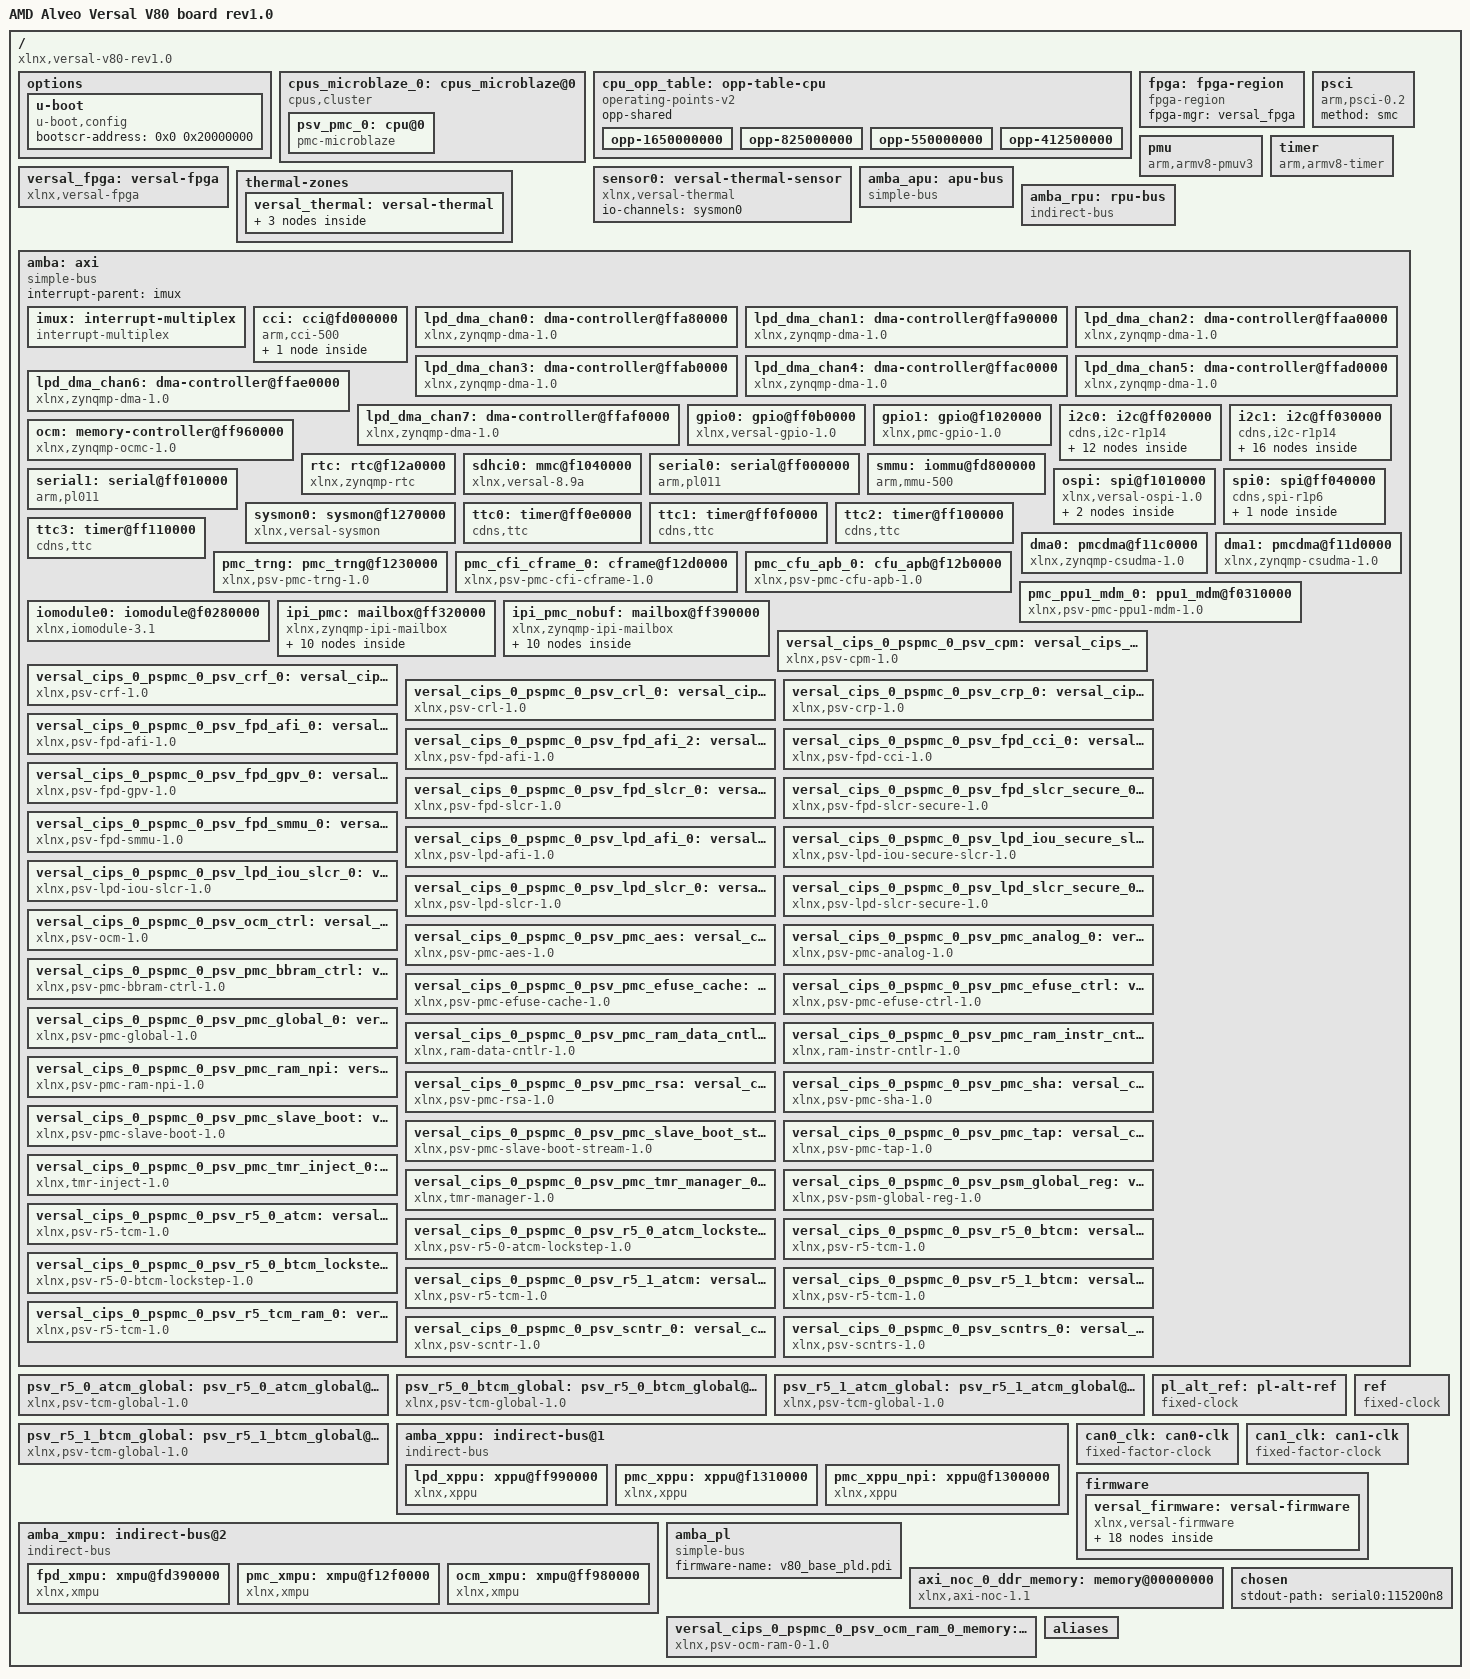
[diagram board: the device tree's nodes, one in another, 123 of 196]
/dts-v1/;
/ {
        compatible = "xlnx,versal-v80-rev1.0", "xlnx,versal";
        #address-cells = <0x2>;
        #size-cells = <0x2>;
        model = "AMD Alveo Versal V80 board rev1.0";
        board = "v80";
        device_id = "xcv80";
        slrcount = <0x3>;
        family = "Versal";
        speed_grade = "2MHP";
        pruned-sdt = <0x1>;

        options {

                u-boot {
                        compatible = "u-boot,config";
                        bootscr-address = <0x0 0x20000000>;
                };
        };

        cpus_microblaze_0: cpus_microblaze@0 {
                #address-cells = <0x1>;
                #size-cells = <0x0>;
                compatible = "cpus,cluster";
                address-map = <0xf0000000 &amba 0xf0000000 0x10000000>,
                 <0x0 &axi_noc_0_ddr_memory 0x0 0x80000000>,
                 <0xff320000 &ipi_pmc 0xff320000 0x10000>,
                 <0xff390000 &ipi_pmc_nobuf 0xff390000 0x10000>,
                 <0xfffc0000 &versal_cips_0_pspmc_0_psv_ocm_ram_0_memory 0xfffc0000 0x40000>,
                 <0xf0310000 &pmc_ppu1_mdm_0 0xf0310000 0x8000>,
                 <0xf1010000 &ospi 0xf1010000 0x10000>,
                 <0xf1020000 &gpio1 0xf1020000 0x10000>,
                 <0xf1040000 &sdhci0 0xf1040000 0x10000>,
                 <0xf1110000 &versal_cips_0_pspmc_0_psv_pmc_global_0 0xf1110000 0x50000>,
                 <0xf1160000 &versal_cips_0_pspmc_0_psv_pmc_analog_0 0xf1160000 0x30000>,
                 <0xf11a0000 &versal_cips_0_pspmc_0_psv_pmc_tap 0xf11a0000 0x20000>,
                 <0xf11c0000 &dma0 0xf11c0000 0x10000>,
                 <0xf11d0000 &dma1 0xf11d0000 0x10000>,
                 <0xf11e0000 &versal_cips_0_pspmc_0_psv_pmc_aes 0xf11e0000 0x10000>,
                 <0xf11f0000 &versal_cips_0_pspmc_0_psv_pmc_bbram_ctrl 0xf11f0000 0x10000>,
                 <0xf1200000 &versal_cips_0_pspmc_0_psv_pmc_rsa 0xf1200000 0x10000>,
                 <0xf1210000 &versal_cips_0_pspmc_0_psv_pmc_sha 0xf1210000 0x10000>,
                 <0xf1220000 &versal_cips_0_pspmc_0_psv_pmc_slave_boot 0xf1220000 0x10000>,
                 <0xf1230000 &pmc_trng 0xf1230000 0x10000>,
                 <0xf1240000 &versal_cips_0_pspmc_0_psv_pmc_efuse_ctrl 0xf1240000 0x10000>,
                 <0xf1250000 &versal_cips_0_pspmc_0_psv_pmc_efuse_cache 0xf1250000 0x10000>,
                 <0xf1260000 &versal_cips_0_pspmc_0_psv_crp_0 0xf1260000 0x10000>,
                 <0xf1270000 &sysmon0 0xf1270000 0x30000>,
                 <0xf12a0000 &rtc 0xf12a0000 0x10000>,
                 <0xf12b0000 &pmc_cfu_apb_0 0xf12b0000 0x10000>,
                 <0xf12d0000 &pmc_cfi_cframe_0 0xf12d0000 0x1000>,
                 <0xf12f0000 &pmc_xmpu 0xf12f0000 0x10000>,
                 <0xf1300000 &pmc_xppu_npi 0xf1300000 0x10000>,
                 <0xf1310000 &pmc_xppu 0xf1310000 0x10000>,
                 <0xf2100000 &versal_cips_0_pspmc_0_psv_pmc_slave_boot_stream 0xf2100000 0x10000>,
                 <0xf6000000 &versal_cips_0_pspmc_0_psv_pmc_ram_npi 0xf6000000 0x2000000>,
                 <0x0 &versal_cips_0_pspmc_0_psv_cpm 0x0 0xfd000000>,
                 <0xfd000000 &cci 0xfd000000 0x100000>,
                 <0xfd1a0000 &versal_cips_0_pspmc_0_psv_crf_0 0xfd1a0000 0x140000>,
                 <0xfd360000 &versal_cips_0_pspmc_0_psv_fpd_afi_0 0xfd360000 0x10000>,
                 <0xfd380000 &versal_cips_0_pspmc_0_psv_fpd_afi_2 0xfd380000 0x10000>,
                 <0xfd390000 &fpd_xmpu 0xfd390000 0x10000>,
                 <0xfd5e0000 &versal_cips_0_pspmc_0_psv_fpd_cci_0 0xfd5e0000 0x10000>,
                 <0xfd5f0000 &versal_cips_0_pspmc_0_psv_fpd_smmu_0 0xfd5f0000 0x10000>,
                 <0xfd610000 &versal_cips_0_pspmc_0_psv_fpd_slcr_0 0xfd610000 0x10000>,
                 <0xfd690000 &versal_cips_0_pspmc_0_psv_fpd_slcr_secure_0 0xfd690000 0x10000>,
                 <0xfd700000 &versal_cips_0_pspmc_0_psv_fpd_gpv_0 0xfd700000 0x100000>,
                 <0xfd800000 &smmu 0xfd800000 0x800000>,
                 <0xff000000 &serial0 0xff000000 0x10000>,
                 <0xff010000 &serial1 0xff010000 0x10000>,
                 <0xff020000 &i2c0 0xff020000 0x10000>,
                 <0xff030000 &i2c1 0xff030000 0x10000>,
                 <0xff040000 &spi0 0xff040000 0x10000>,
                 <0xff080000 &versal_cips_0_pspmc_0_psv_lpd_iou_slcr_0 0xff080000 0x20000>,
                 <0xff0a0000 &versal_cips_0_pspmc_0_psv_lpd_iou_secure_slcr_0 0xff0a0000 0x10000>,
                 <0xff0b0000 &gpio0 0xff0b0000 0x10000>,
                 <0xff0e0000 &ttc0 0xff0e0000 0x10000>,
                 <0xff0f0000 &ttc1 0xff0f0000 0x10000>,
                 <0xff100000 &ttc2 0xff100000 0x10000>,
                 <0xff110000 &ttc3 0xff110000 0x10000>,
                 <0xff130000 &versal_cips_0_pspmc_0_psv_scntr_0 0xff130000 0x10000>,
                 <0xff140000 &versal_cips_0_pspmc_0_psv_scntrs_0 0xff140000 0x10000>,
                 <0xff410000 &versal_cips_0_pspmc_0_psv_lpd_slcr_0 0xff410000 0x100000>,
                 <0xff510000 &versal_cips_0_pspmc_0_psv_lpd_slcr_secure_0 0xff510000 0x40000>,
                 <0xff5e0000 &versal_cips_0_pspmc_0_psv_crl_0 0xff5e0000 0x300000>,
                 <0xff960000 &versal_cips_0_pspmc_0_psv_ocm_ctrl 0xff960000 0x10000>,
                 <0xff980000 &ocm_xmpu 0xff980000 0x10000>,
                 <0xff990000 &lpd_xppu 0xff990000 0x10000>,
                 <0xff9b0000 &versal_cips_0_pspmc_0_psv_lpd_afi_0 0xff9b0000 0x10000>,
                 <0xffa80000 &lpd_dma_chan0 0xffa80000 0x10000>,
                 <0xffa90000 &lpd_dma_chan1 0xffa90000 0x10000>,
                 <0xffaa0000 &lpd_dma_chan2 0xffaa0000 0x10000>,
                 <0xffab0000 &lpd_dma_chan3 0xffab0000 0x10000>,
                 <0xffac0000 &lpd_dma_chan4 0xffac0000 0x10000>,
                 <0xffad0000 &lpd_dma_chan5 0xffad0000 0x10000>,
                 <0xffae0000 &lpd_dma_chan6 0xffae0000 0x10000>,
                 <0xffaf0000 &lpd_dma_chan7 0xffaf0000 0x10000>,
                 <0xffc90000 &versal_cips_0_pspmc_0_psv_psm_global_reg 0xffc90000 0xf000>,
                 <0xffe00000 &psv_r5_0_atcm_global 0xffe00000 0x40000>,
                 <0xffe90000 &psv_r5_1_atcm_global 0xffe90000 0x10000>,
                 <0xffeb0000 &psv_r5_1_btcm_global 0xffeb0000 0x10000>,
                 <0xf0083000 &versal_cips_0_pspmc_0_psv_pmc_tmr_inject_0 0xf0083000 0x1000>,
                 <0xf0200000 &versal_cips_0_pspmc_0_psv_pmc_ram_instr_cntlr 0xf0200000 0x40000>,
                 <0xf0240000 &versal_cips_0_pspmc_0_psv_pmc_ram_data_cntlr 0xf0240000 0x20000>,
                 <0xf0280000 &iomodule0 0xf0280000 0x1000>,
                 <0xf0283000 &versal_cips_0_pspmc_0_psv_pmc_tmr_manager_0 0xf0283000 0x1000>;
                #ranges-address-cells = <0x1>;
                #ranges-size-cells = <0x1>;
                phandle = <0xa3>;

                psv_pmc_0: cpu@0 {
                        compatible = "pmc-microblaze";
                        device_type = "cpu";
                        reg = <0x0>;
                        operating-points-v2 = <&cpu_opp_table>;
                        xlnx,d-axi = <0x1>;
                        xlnx,addr-tag-bits = <0x0>;
                        xlnx,m-axi-dc-thread-id-width = <0x1>;
                        xlnx,m0-axis-protocol = "GENERIC";
                        xlnx,dcache-force-tag-lutram = <0x0>;
                        xlnx,interrupt-is-edge = <0x0>;
                        xlnx,use-mmu = <0x0>;
                        xlnx,m-axi-dp-exclusive-access = <0x0>;
                        xlnx,use-reorder-instr = <0x1>;
                        xlnx,m14-axis-protocol = "GENERIC";
                        xlnx,use-div = <0x1>;
                        xlnx,dc-axi-mon = <0x0>;
                        xlnx,m-axi-ic-user-signals = <0x0>;
                        xlnx,use-config-reset = <0x0>;
                        xlnx,s14-axis-protocol = "GENERIC";
                        xlnx,mmu-zones = <0x10>;
                        xlnx,enable-discrete-ports = <0x0>;
                        xlnx,d-lmb = <0x1>;
                        xlnx,m-axi-dc-exclusive-access = <0x0>;
                        xlnx,debug-interface = <0x0>;
                        xlnx,s9-axis-protocol = "GENERIC";
                        xlnx,sco = <0x0>;
                        xlnx,use-ext-brk = <0x0>;
                        xlnx,debug-enabled = <0x1>;
                        xlnx,daddr-size = <0x20>;
                        xlnx,s0-axis-data-width = <0x20>;
                        xlnx,use-extended-fsl-instr = <0x0>;
                        xlnx,m-axi-dc-user-signals = <0x0>;
                        xlnx,reset-msr = <0x0>;
                        xlnx,branch-target-cache-size = <0x0>;
                        xlnx,s2-axis-data-width = <0x20>;
                        xlnx,cache-byte-size = <0x2000>;
                        bus-handle = <0x1>;
                        xlnx,mmu-tlb-access = <0x3>;
                        xlnx,s4-axis-data-width = <0x20>;
                        xlnx,m-axi-ic-awuser-width = <0x5>;
                        xlnx,s6-axis-data-width = <0x20>;
                        xlnx,s4-axis-protocol = "GENERIC";
                        xlnx,s8-axis-data-width = <0x20>;
                        xlnx,edk-special = "microblaze";
                        xlnx,use-dcache = <0x0>;
                        xlnx,m-axi-dp-addr-width = <0x20>;
                        xlnx,m-axi-ic-wuser-width = <0x1>;
                        xlnx,i-axi = <0x0>;
                        xlnx,icache-streams = <0x0>;
                        xlnx,m-axi-dc-awuser-width = <0x5>;
                        xlnx,pss-ref-clk-freq = <0x1fca034>;
                        xlnx,use-stack-protection = <0x1>;
                        xlnx,m6-axis-protocol = "GENERIC";
                        xlnx,num-sync-ff-dbg-clk = <0x1>;
                        xlnx,m-axi-ip-data-width = <0x20>;
                        d-cache-size = <0x2000>;
                        xlnx,use-pcmp-instr = <0x1>;
                        xlnx,area-optimized = <0x0>;
                        xlnx,avoid-primitives = <0x0>;
                        xlnx,m1-axis-protocol = "GENERIC";
                        xlnx,i-lmb = <0x1>;
                        xlnx,lockstep-select = <0x0>;
                        xlnx,dcache-data-width = <0x0>;
                        xlnx,icache-force-tag-lutram = <0x0>;
                        xlnx,m15-axis-protocol = "GENERIC";
                        xlnx,use-branch-target-cache = <0x0>;
                        xlnx,m-axi-ip-thread-id-width = <0x1>;
                        xlnx,mmu-itlb-size = <0x2>;
                        xlnx,number-of-pc-brk = <0x2>;
                        xlnx,imprecise-exceptions = <0x0>;
                        xlnx,m-axi-ic-buser-width = <0x1>;
                        xlnx,m-axi-ic-addr-width = <0x20>;
                        xlnx,s15-axis-protocol = "GENERIC";
                        d-cache-highaddr = <0x3fffffff>;
                        xlnx,m10-axis-protocol = "GENERIC";
                        xlnx,optimization = <0x0>;
                        xlnx,m-axi-ic-aruser-width = <0x5>;
                        xlnx,d-lmb-mon = <0x0>;
                        xlnx,s10-axis-protocol = "GENERIC";
                        xlnx,m-axi-ic-ruser-width = <0x1>;
                        xlnx,s5-axis-protocol = "GENERIC";
                        xlnx,fault-tolerant = <0x1>;
                        d-cache-line-size = <0x10>;
                        xlnx,m-axi-dc-aruser-width = <0x5>;
                        xlnx,mmu-privileged-instr = <0x0>;
                        xlnx,m-axi-i-bus-exception = <0x0>;
                        xlnx,reset-msr-eip = <0x0>;
                        xlnx,endianness = <0x1>;
                        xlnx,reset-msr-ice = <0x0>;
                        xlnx,dp-axi-mon = <0x0>;
                        xlnx,s10-axis-data-width = <0x20>;
                        xlnx,s0-axis-protocol = "GENERIC";
                        xlnx,s12-axis-data-width = <0x20>;
                        xlnx,m7-axis-protocol = "GENERIC";
                        xlnx,s14-axis-data-width = <0x20>;
                        xlnx,m-axi-d-bus-exception = <0x1>;
                        xlnx,reset-msr-bip = <0x1>;
                        xlnx,debug-external-trace = <0x0>;
                        xlnx,addr-size = <0x20>;
                        xlnx,m-axi-ic-user-value = <0x1f>;
                        xlnx,m1-axis-data-width = <0x20>;
                        xlnx,debug-event-counters = <0x5>;
                        xlnx,m3-axis-data-width = <0x20>;
                        xlnx,fpu-exception = <0x0>;
                        xlnx,m2-axis-protocol = "GENERIC";
                        xlnx,m5-axis-data-width = <0x20>;
                        xlnx,m7-axis-data-width = <0x20>;
                        xlnx,edk-iptype = "PROCESSOR";
                        xlnx,debug-latency-counters = <0x1>;
                        xlnx,interconnect = <0x2>;
                        xlnx,m9-axis-data-width = <0x20>;
                        xlnx,edge-is-positive = <0x1>;
                        xlnx,use-icache = <0x0>;
                        xlnx,async-wakeup = <0x3>;
                        xlnx,m10-axis-data-width = <0x20>;
                        xlnx,m12-axis-data-width = <0x20>;
                        xlnx,use-ext-nm-brk = <0x0>;
                        xlnx,m11-axis-protocol = "GENERIC";
                        xlnx,m14-axis-data-width = <0x20>;
                        xlnx,icache-always-used = <0x0>;
                        xlnx,ic-axi-mon = <0x0>;
                        xlnx,num-sync-ff-clk-irq = <0x1>;
                        xlnx,freq = <0x1312d000>;
                        xlnx,lockstep-master = <0x0>;
                        xlnx,s11-axis-protocol = "GENERIC";
                        xlnx,use-msr-instr = <0x1>;
                        xlnx,s6-axis-protocol = "GENERIC";
                        xlnx,iaddr-size = <0x20>;
                        xlnx,interrupt-mon = <0x0>;
                        xlnx,m-axi-dc-data-width = <0x20>;
                        xlnx,dynamic-bus-sizing = <0x0>;
                        xlnx,number-of-wr-addr-brk = <0x1>;
                        xlnx,use-interrupt = <0x1>;
                        xlnx,m-axi-ip-addr-width = <0x20>;
                        xlnx,async-interrupt = <0x1>;
                        xlnx,pc-width = <0x20>;
                        xlnx,icache-victims = <0x0>;
                        xlnx,reset-msr-ee = <0x0>;
                        xlnx,s1-axis-protocol = "GENERIC";
                        xlnx,m8-axis-protocol = "GENERIC";
                        i-cache-baseaddr = <0x0>;
                        xlnx,i-lmb-mon = <0x0>;
                        xlnx,dcache-byte-size = <0x2000>;
                        xlnx,m-axi-dp-thread-id-width = <0x1>;
                        xlnx,data-size = <0x20>;
                        xlnx,m-axi-dc-wuser-width = <0x1>;
                        xlnx,fsl-exception = <0x0>;
                        xlnx,m3-axis-protocol = "GENERIC";
                        xlnx,s1-axis-data-width = <0x20>;
                        xlnx,dcache-use-writeback = <0x0>;
                        xlnx,div-zero-exception = <0x1>;
                        xlnx,s3-axis-data-width = <0x20>;
                        xlnx,base-vectors = <0xf0240000>;
                        xlnx,icache-line-len = <0x4>;
                        xlnx,s5-axis-data-width = <0x20>;
                        xlnx,s7-axis-data-width = <0x20>;
                        xlnx,allow-dcache-wr = <0x1>;
                        xlnx,s9-axis-data-width = <0x20>;
                        xlnx,use-barrel = <0x1>;
                        xlnx,g-use-exceptions = <0x1>;
                        xlnx,dcache-line-len = <0x4>;
                        xlnx,m12-axis-protocol = "GENERIC";
                        xlnx,num-sync-ff-clk = <0x2>;
                        i-cache-size = <0x2000>;
                        xlnx,instance = "design_1_microblaze_0_0";
                        xlnx,reset-msr-ie = <0x0>;
                        xlnx,s12-axis-protocol = "GENERIC";
                        xlnx,dcache-addr-tag = <0x0>;
                        xlnx,m-axi-ic-thread-id-width = <0x1>;
                        xlnx,number-of-rd-addr-brk = <0x1>;
                        xlnx,m-axi-dc-buser-width = <0x1>;
                        xlnx,s7-axis-protocol = "GENERIC";
                        xlnx,lockstep-slave = <0x0>;
                        xlnx,debug-profile-size = <0x0>;
                        xlnx,s2-axis-protocol = "GENERIC";
                        xlnx,m9-axis-protocol = "GENERIC";
                        xlnx,debug-counter-width = <0x20>;
                        xlnx,icache-data-width = <0x0>;
                        xlnx,m-axi-dc-ruser-width = <0x1>;
                        xlnx,reset-msr-dce = <0x0>;
                        xlnx,ip-name = "psv_pmc";
                        xlnx,ip-axi-mon = <0x0>;
                        xlnx,m-axi-dp-data-width = <0x20>;
                        xlnx,m4-axis-protocol = "GENERIC";
                        xlnx,dcache-always-used = <0x0>;
                        xlnx,ill-opcode-exception = <0x1>;
                        xlnx,trace = <0x1>;
                        xlnx,pvr = <0x2>;
                        xlnx,debug-trace-size = <0x2000>;
                        i-cache-line-size = <0x10>;
                        xlnx,m13-axis-protocol = "GENERIC";
                        xlnx,s11-axis-data-width = <0x20>;
                        xlnx,m-axi-dc-addr-width = <0x20>;
                        xlnx,s13-axis-data-width = <0x20>;
                        xlnx,ecc-use-ce-exception = <0x0>;
                        xlnx,opcode-0x0-illegal = <0x1>;
                        xlnx,pvr-user2 = <0x0>;
                        xlnx,s15-axis-data-width = <0x20>;
                        xlnx,s13-axis-protocol = "GENERIC";
                        xlnx,m0-axis-data-width = <0x20>;
                        i-cache-highaddr = <0x3fffffff>;
                        xlnx,s8-axis-protocol = "GENERIC";
                        xlnx,m2-axis-data-width = <0x20>;
                        xlnx,num-sync-ff-clk-debug = <0x2>;
                        xlnx,allow-icache-wr = <0x1>;
                        xlnx,m4-axis-data-width = <0x20>;
                        xlnx,g-template-list = <0x0>;
                        xlnx,m6-axis-data-width = <0x20>;
                        xlnx,m-axi-ic-data-width = <0x20>;
                        xlnx,m8-axis-data-width = <0x20>;
                        xlnx,use-hw-mul = <0x2>;
                        xlnx,use-fpu = <0x0>;
                        xlnx,s3-axis-protocol = "GENERIC";
                        xlnx,use-non-secure = <0x0>;
                        d-cache-baseaddr = <0x0>;
                        xlnx,m11-axis-data-width = <0x20>;
                        xlnx,m13-axis-data-width = <0x20>;
                        xlnx,instr-size = <0x20>;
                        xlnx,m15-axis-data-width = <0x20>;
                        xlnx,mmu-dtlb-size = <0x4>;
                        xlnx,fsl-links = <0x0>;
                        xlnx,m5-axis-protocol = "GENERIC";
                        xlnx,dcache-victims = <0x0>;
                        xlnx,m-axi-dc-user-value = <0x1f>;
                        xlnx,unaligned-exceptions = <0x1>;
                        phandle = <0xa4>;
                };
        };

        cpu_opp_table: opp-table-cpu {
                compatible = "operating-points-v2";
                opp-shared;
                phandle = <0x74>;

                opp-1650000000 {
                        opp-hz = <0x0 0x62590080>;
                        clock-latency-ns = <0x7a120>;
                        opp-microvolt = <0xf4240>;
                };

                opp-825000000 {
                        opp-hz = <0x0 0x312c8040>;
                        clock-latency-ns = <0x7a120>;
                        opp-microvolt = <0xf4240>;
                };

                opp-550000000 {
                        opp-hz = <0x0 0x20c85580>;
                        clock-latency-ns = <0x7a120>;
                        opp-microvolt = <0xf4240>;
                };

                opp-412500000 {
                        opp-hz = <0x0 0x18964020>;
                        clock-latency-ns = <0x7a120>;
                        opp-microvolt = <0xf4240>;
                };
        };

        fpga: fpga-region {
                compatible = "fpga-region";
                fpga-mgr = <&versal_fpga>;
                #address-cells = <0x2>;
                #size-cells = <0x2>;
                phandle = <0xac>;
        };

        psci: psci {
                compatible = "arm,psci-0.2";
                method = "smc";
                phandle = <0xad>;
        };

        pmu {
                compatible = "arm,armv8-pmuv3";
                interrupt-parent = <&imux>;
                interrupts = <0x1 0x7 0x304>;
        };

        timer: timer {
                compatible = "arm,armv8-timer";
                interrupt-parent = <&imux>;
                interrupts = <0x1 0xd 0x4 0x1 0xe 0x4 0x1 0xb 0x4 0x1 0xa 0x4>;
                phandle = <0xae>;
        };

        versal_fpga: versal-fpga {
                compatible = "xlnx,versal-fpga";
                phandle = <0x94>;
        };

        sensor0: versal-thermal-sensor {
                compatible = "xlnx,versal-thermal";
                #thermal-sensor-cells = <0x0>;
                io-channels = <&sysmon0>;
                io-channel-names = "sysmon-temp-channel";
                phandle = <0x96>;
        };

        thermal-zones {

                versal_thermal: versal-thermal {
                        polling-delay-passive = <0xfa>;
                        polling-delay = <0x3e8>;
                        thermal-sensors = <0x96>;
                        phandle = <0xaf>;

                        trips {

                                temp_alert: temp-alert {
                                        temperature = <0x11170>;
                                        hysteresis = <0x0>;
                                        type = "passive";
                                        phandle = <0xb0>;
                                };

                                ot_crit: ot-crit {
                                        temperature = <0x1e848>;
                                        hysteresis = <0x0>;
                                        type = "critical";
                                        phandle = <0xb1>;
                                };
                        };
                };
        };

        amba_apu: apu-bus {
                compatible = "simple-bus";
                #address-cells = <0x2>;
                #size-cells = <0x2>;
                ranges;
                bootph-all;
                phandle = <0x2>;
        };

        amba_rpu: rpu-bus {
                compatible = "indirect-bus";
                #address-cells = <0x2>;
                #size-cells = <0x2>;
                ranges;
                bootph-all;
                phandle = <0x85>;
        };

        amba: axi {
                compatible = "simple-bus";
                #address-cells = <0x2>;
                #size-cells = <0x2>;
                ranges;
                interrupt-parent = <&imux>;
                bootph-all;
                phandle = <0x1>;

                imux: interrupt-multiplex {
                        compatible = "interrupt-multiplex";
                        #address-cells = <0x0>;
                        #interrupt-cells = <0x3>;
                        interrupt-controller;
                        interrupt-map-mask = <0x0 0xffff 0x0>;
                        interrupt-map = <0x0 0x14 0x0 0x44 0x0 0x14 0x1 0x0 0x15 0x0 0x44 0x0 0x15 0x1 0x0 0x6a 0x0 0x44 0x0 0x6a 0x4 0x0 0x3c 0x0 0x44 0x0 0x3c 0x4 0x0 0x3d 0x0 0x44 0x0 0x3d 0x4 0x0 0x3e 0x0 0x44 0x0 0x3e 0x4 0x0 0x3f 0x0 0x44 0x0 0x3f 0x4 0x0 0x40 0x0 0x44 0x0 0x40 0x4 0x0 0x41 0x0 0x44 0x0 0x41 0x4 0x0 0x42 0x0 0x44 0x0 0x42 0x4 0x0 0x43 0x0 0x44 0x0 0x43 0x4 0x0 0x38 0x0 0x44 0x0 0x38 0x4 0x0 0x3a 0x0 0x44 0x0 0x3a 0x4 0x0 0xd 0x0 0x44 0x0 0xd 0x4 0x0 0x7a 0x0 0x44 0x0 0x7a 0x4 0x0 0xe 0x0 0x44 0x0 0xe 0x4 0x0 0xf 0x0 0x44 0x0 0xf 0x4 0x0 0x8e 0x0 0x44 0x0 0x8e 0x4 0x0 0x8f 0x0 0x44 0x0 0x8f 0x4 0x0 0x7e 0x0 0x44 0x0 0x7e 0x4 0x0 0x80 0x0 0x44 0x0 0x80 0x4 0x0 0x12 0x0 0x44 0x0 0x12 0x4 0x0 0x13 0x0 0x44 0x0 0x13 0x4 0x0 0x6b 0x0 0x44 0x0 0x6b 0x4 0x0 0x7c 0x0 0x44 0x0 0x7c 0x4 0x0 0x7d 0x0 0x44 0x0 0x7d 0x4 0x0 0x10 0x0 0x44 0x0 0x10 0x4 0x0 0x11 0x0 0x44 0x0 0x11 0x4 0x0 0x16 0x0 0x44 0x0 0x16 0x4 0x0 0x1a 0x0 0x44 0x0 0x1a 0x4 0x0 0x4a 0x0 0x44 0x0 0x4a 0x4 0x0 0x48 0x0 0x44 0x0 0x48 0x4 0x0 0x1e 0x0 0x44 0x0 0x1e 0x4 0x0 0x1f 0x0 0x44 0x0 0x1f 0x4 0x0 0x83 0x0 0x44 0x0 0x83 0x4 0x0 0x84 0x0 0x44 0x0 0x84 0x4 0x0 0x14 0x0 0x8b 0x0 0x14 0x1 0x0 0x15 0x0 0x8b 0x0 0x15 0x1 0x0 0x6a 0x0 0x8b 0x0 0x6a 0x4 0x0 0x3c 0x0 0x8b 0x0 0x3c 0x4 0x0 0x3d 0x0 0x8b 0x0 0x3d 0x4 0x0 0x3e 0x0 0x8b 0x0 0x3e 0x4 0x0 0x3f 0x0 0x8b 0x0 0x3f 0x4 0x0 0x40 0x0 0x8b 0x0 0x40 0x4 0x0 0x41 0x0 0x8b 0x0 0x41 0x4 0x0 0x42 0x0 0x8b 0x0 0x42 0x4 0x0 0x43 0x0 0x8b 0x0 0x43 0x4 0x0 0x38 0x0 0x8b 0x0 0x38 0x4 0x0 0x3a 0x0 0x8b 0x0 0x3a 0x4 0x0 0xd 0x0 0x8b 0x0 0xd 0x4 0x0 0x7a 0x0 0x8b 0x0 0x7a 0x4 0x0 0xe 0x0 0x8b 0x0 0xe 0x4 0x0 0xf 0x0 0x8b 0x0 0xf 0x4 0x0 0x8e 0x0 0x8b 0x0 0x8e 0x4 0x0 0x8f 0x0 0x8b 0x0 0x8f 0x4 0x0 0x7e 0x0 0x8b 0x0 0x7e 0x4 0x0 0x80 0x0 0x8b 0x0 0x80 0x4 0x0 0x12 0x0 0x8b 0x0 0x12 0x4 0x0 0x13 0x0 0x8b 0x0 0x13 0x4 0x0 0x6b 0x0 0x8b 0x0 0x6b 0x4 0x0 0x7c 0x0 0x8b 0x0 0x7c 0x4 0x0 0x7d 0x0 0x8b 0x0 0x7d 0x4 0x0 0x10 0x0 0x8b 0x0 0x10 0x4 0x0 0x11 0x0 0x8b 0x0 0x11 0x4 0x0 0x16 0x0 0x8b 0x0 0x16 0x4 0x0 0x1a 0x0 0x8b 0x0 0x1a 0x4 0x0 0x4a 0x0 0x8b 0x0 0x4a 0x4 0x0 0x48 0x0 0x8b 0x0 0x48 0x4 0x0 0x1e 0x0 0x8b 0x0 0x1e 0x4 0x0 0x1f 0x0 0x8b 0x0 0x1f 0x4 0x0 0x83 0x0 0x8b 0x0 0x83 0x4 0x0 0x84 0x0 0x8b 0x0 0x84 0x4>;
                        phandle = <0x95>;
                };

                cci: cci@fd000000 {
                        compatible = "arm,cci-500";
                        status = "okay";
                        reg = <0x0 0xfd000000 0x0 0x10000>;
                        ranges = <0x0 0x0 0xfd000000 0xa0000>;
                        #address-cells = <0x1>;
                        #size-cells = <0x1>;
                        xlnx,ip-name = "psv_fpd_maincci";
                        xlnx,name = "versal_cips_0_pspmc_0_psv_fpd_maincci_0";
                        phandle = <0x46>;

                        cci_pmu: pmu@10000 {
                                compatible = "arm,cci-500-pmu,r0";
                                reg = <0x10000 0x90000>;
                                interrupt-parent = <&imux>;
                                interrupts = <0x0 0x6a 0x4 0x0 0x6a 0x4 0x0 0x6a 0x4 0x0 0x6a 0x4 0x0 0x6a 0x4 0x0 0x6a 0x4 0x0 0x6a 0x4 0x0 0x6a 0x4>;
                                phandle = <0xb4>;
                        };
                };

                lpd_dma_chan0: dma-controller@ffa80000 {
                        compatible = "xlnx,zynqmp-dma-1.0";
                        status = "okay";
                        reg = <0x0 0xffa80000 0x0 0x1000>;
                        interrupts = <0x0 0x3c 0x4>;
                        interrupt-parent = <&imux>;
                        clock-names = "clk_main", "clk_apb";
                        xlnx,dma-type = <0x1>;
                        #dma-cells = <0x1>;
                        xlnx,bus-width = <0x40>;
                        clocks = <&versal_clk 0x51>,
                         <&versal_clk 0x52>;
                        power-domains = <&versal_firmware 0x18224035>;
                        xlnx,is-cache-coherent = <0x0>;
                        xlnx,ip-name = "psv_adma";
                        xlnx,dma-mode = <0x1>;
                        xlnx,name = "versal_cips_0_pspmc_0_psv_adma_0";
                        phandle = <0x68>;
                };

                lpd_dma_chan1: dma-controller@ffa90000 {
                        compatible = "xlnx,zynqmp-dma-1.0";
                        status = "okay";
                        reg = <0x0 0xffa90000 0x0 0x1000>;
                        interrupts = <0x0 0x3d 0x4>;
                        interrupt-parent = <&imux>;
                        clock-names = "clk_main", "clk_apb";
                        xlnx,dma-type = <0x1>;
                        #dma-cells = <0x1>;
                        xlnx,bus-width = <0x40>;
                        clocks = <&versal_clk 0x51>,
                         <&versal_clk 0x52>;
                        power-domains = <&versal_firmware 0x18224036>;
                        xlnx,is-cache-coherent = <0x0>;
                        xlnx,ip-name = "psv_adma";
                        xlnx,dma-mode = <0x1>;
                        xlnx,name = "versal_cips_0_pspmc_0_psv_adma_1";
                        phandle = <0x69>;
                };

                lpd_dma_chan2: dma-controller@ffaa0000 {
                        compatible = "xlnx,zynqmp-dma-1.0";
                        status = "okay";
                        reg = <0x0 0xffaa0000 0x0 0x1000>;
                        interrupts = <0x0 0x3e 0x4>;
                        interrupt-parent = <&imux>;
                        clock-names = "clk_main", "clk_apb";
                        xlnx,dma-type = <0x1>;
                        #dma-cells = <0x1>;
                        xlnx,bus-width = <0x40>;
                        clocks = <&versal_clk 0x51>,
                         <&versal_clk 0x52>;
                        power-domains = <&versal_firmware 0x18224037>;
                        xlnx,is-cache-coherent = <0x0>;
                        xlnx,ip-name = "psv_adma";
                        xlnx,dma-mode = <0x1>;
                        xlnx,name = "versal_cips_0_pspmc_0_psv_adma_2";
                        phandle = <0x6a>;
                };

                lpd_dma_chan3: dma-controller@ffab0000 {
                        compatible = "xlnx,zynqmp-dma-1.0";
                        status = "okay";
                        reg = <0x0 0xffab0000 0x0 0x1000>;
                        interrupts = <0x0 0x3f 0x4>;
                        interrupt-parent = <&imux>;
                        clock-names = "clk_main", "clk_apb";
                        xlnx,dma-type = <0x1>;
                        #dma-cells = <0x1>;
                        xlnx,bus-width = <0x40>;
                        clocks = <&versal_clk 0x51>,
                         <&versal_clk 0x52>;
                        power-domains = <&versal_firmware 0x18224038>;
                        xlnx,is-cache-coherent = <0x0>;
                        xlnx,ip-name = "psv_adma";
                        xlnx,dma-mode = <0x1>;
                        xlnx,name = "versal_cips_0_pspmc_0_psv_adma_3";
                        phandle = <0x6b>;
                };

                lpd_dma_chan4: dma-controller@ffac0000 {
                        compatible = "xlnx,zynqmp-dma-1.0";
                        status = "okay";
                        reg = <0x0 0xffac0000 0x0 0x1000>;
                        interrupts = <0x0 0x40 0x4>;
                        interrupt-parent = <&imux>;
                        clock-names = "clk_main", "clk_apb";
                        xlnx,dma-type = <0x1>;
                        #dma-cells = <0x1>;
                        xlnx,bus-width = <0x40>;
                        clocks = <&versal_clk 0x51>,
                         <&versal_clk 0x52>;
                        power-domains = <&versal_firmware 0x18224039>;
                        xlnx,is-cache-coherent = <0x0>;
                        xlnx,ip-name = "psv_adma";
                        xlnx,dma-mode = <0x1>;
                        xlnx,name = "versal_cips_0_pspmc_0_psv_adma_4";
                        phandle = <0x6c>;
                };

                lpd_dma_chan5: dma-controller@ffad0000 {
                        compatible = "xlnx,zynqmp-dma-1.0";
                        status = "okay";
                        reg = <0x0 0xffad0000 0x0 0x1000>;
                        interrupts = <0x0 0x41 0x4>;
                        interrupt-parent = <&imux>;
                        clock-names = "clk_main", "clk_apb";
                        xlnx,dma-type = <0x1>;
                        #dma-cells = <0x1>;
                        xlnx,bus-width = <0x40>;
                        clocks = <&versal_clk 0x51>,
                         <&versal_clk 0x52>;
                        power-domains = <&versal_firmware 0x1822403a>;
                        xlnx,is-cache-coherent = <0x0>;
                        xlnx,ip-name = "psv_adma";
                        xlnx,dma-mode = <0x1>;
                        xlnx,name = "versal_cips_0_pspmc_0_psv_adma_5";
                        phandle = <0x6d>;
                };

                lpd_dma_chan6: dma-controller@ffae0000 {
                        compatible = "xlnx,zynqmp-dma-1.0";
                        status = "okay";
                        reg = <0x0 0xffae0000 0x0 0x1000>;
                        interrupts = <0x0 0x42 0x4>;
                        interrupt-parent = <&imux>;
                        clock-names = "clk_main", "clk_apb";
                        xlnx,dma-type = <0x1>;
                        #dma-cells = <0x1>;
                        xlnx,bus-width = <0x40>;
                        clocks = <&versal_clk 0x51>,
                         <&versal_clk 0x52>;
                        power-domains = <&versal_firmware 0x1822403b>;
                        xlnx,is-cache-coherent = <0x0>;
                        xlnx,ip-name = "psv_adma";
                        xlnx,dma-mode = <0x1>;
                        xlnx,name = "versal_cips_0_pspmc_0_psv_adma_6";
                        phandle = <0x6e>;
                };

                lpd_dma_chan7: dma-controller@ffaf0000 {
                        compatible = "xlnx,zynqmp-dma-1.0";
                        status = "okay";
                        reg = <0x0 0xffaf0000 0x0 0x1000>;
                        interrupts = <0x0 0x43 0x4>;
                        interrupt-parent = <&imux>;
                        clock-names = "clk_main", "clk_apb";
                        xlnx,dma-type = <0x1>;
                        #dma-cells = <0x1>;
                        xlnx,bus-width = <0x40>;
                        clocks = <&versal_clk 0x51>,
                         <&versal_clk 0x52>;
                        power-domains = <&versal_firmware 0x1822403c>;
                        xlnx,is-cache-coherent = <0x0>;
                        xlnx,ip-name = "psv_adma";
                        xlnx,dma-mode = <0x1>;
                        xlnx,name = "versal_cips_0_pspmc_0_psv_adma_7";
                        phandle = <0x6f>;
                };

                gpio0: gpio@ff0b0000 {
                        compatible = "xlnx,versal-gpio-1.0";
                        status = "okay";
                        reg = <0x0 0xff0b0000 0x0 0x1000>;
                        interrupts = <0x0 0xd 0x4>;
                        interrupt-parent = <&imux>;
                        #gpio-cells = <0x2>;
                        gpio-controller;
                        #interrupt-cells = <0x2>;
                        interrupt-controller;
                        clocks = <&versal_clk 0x52>;
                        power-domains = <&versal_firmware 0x18224023>;
                        xlnx,ip-name = "psv_gpio";
                        emio-gpio-width = "";
                        xlnx,name = "versal_cips_0_pspmc_0_psv_gpio_2";
                        gpio-line-names = [49 32 43 5F 51 53 46 50 5F 53 43 4C 00 49 32 43 5F 51 53 46 50 5F 53 44 41 00 49 32 43 5F 4D 41 49 4E 5F 53 43 4C 00 49 32 43 5F 4D 41 49 4E 5F 53 44 41 00 49 32 43 5F 4D 41 49 4E 5F 52 53 54 5F 42 00 49 32 43 5F 4D 41 49 4E 5F 49 4E 54 52 5F 42 00 51 53 46 50 34 5F 49 4F 45 58 50 5F 52 53 54 00 51 53 46 50 33 5F 49 4F 45 58 50 5F 52 53 54 00 4C 50 44 5F 55 41 52 54 30 5F 52 58 44 00 4C 50 44 5F 55 41 52 54 30 5F 54 58 44 00 00 00 53 50 49 30 5F 53 43 4C 4B 00 49 32 43 5F 51 53 46 50 5F 52 53 54 5F 42 00 49 32 43 5F 51 53 46 50 5F 49 4E 54 52 5F 42 00 53 50 49 30 5F 43 53 5F 42 00 53 50 49 30 5F 4D 49 53 4F 00 53 50 49 30 5F 4D 4F 53 49 00 51 53 46 50 31 5F 49 4F 45 58 50 5F 52 53 54 00 51 53 46 50 32 5F 49 4F 45 58 50 5F 52 53 54 00 4C 50 44 5F 55 41 52 54 31 5F 54 58 44 00 4C 50 44 5F 55 41 52 54 31 5F 52 58 44 00 42 4F 41 52 44 5F 53 54 41 54 55 53 5F 4C 45 44 5F 52 00 42 4F 41 52 44 5F 53 54 41 54 55 53 5F 4C 45 44 5F 47 00 42 4F 41 52 44 5F 53 54 41 54 55 53 5F 4C 45 44 5F 42 00 00 00 00 00 00 00 00 00 00 00 00 00 00 00 00 00 00 00 00 00 00 00 00 00 00 00 00 00 00 00 00 00 00];
                        phandle = <0x59>;
                };

                gpio1: gpio@f1020000 {
                        compatible = "xlnx,pmc-gpio-1.0";
                        status = "okay";
                        reg = <0x0 0xf1020000 0x0 0x1000>;
                        interrupts = <0x0 0x7a 0x4>;
                        interrupt-parent = <&imux>;
                        #gpio-cells = <0x2>;
                        gpio-controller;
                        #interrupt-cells = <0x2>;
                        interrupt-controller;
                        clocks = <&versal_clk 0x3d>;
                        power-domains = <&versal_firmware 0x1822402c>;
                        xlnx,ip-name = "psv_pmc_gpio";
                        xlnx,name = "versal_cips_0_pspmc_0_psv_pmc_gpio_0";
                        gpio-line-names = [00 00 00 00 00 00 00 00 00 00 00 42 4F 41 52 44 5F 49 44 00 4F 53 50 49 5F 52 45 53 45 54 5F 42 00 00 00 00 00 00 00 00 00 00 00 00 50 43 49 45 5F 52 53 54 31 5F 42 00 50 43 49 45 5F 52 53 54 32 5F 42 00 51 53 46 50 34 5F 41 43 54 5F 4C 45 44 00 51 53 46 50 34 5F 4C 4E 4B 5F 47 52 5F 4C 45 44 00 51 53 46 50 34 5F 4C 4E 4B 5F 59 4C 5F 4C 45 44 00 45 4E 5F 33 56 33 5F 4D 43 49 4F 00 51 53 46 50 33 5F 41 43 54 5F 4C 45 44 00 51 53 46 50 33 5F 4C 4E 4B 5F 47 52 5F 4C 45 44 00 51 53 46 50 33 5F 4C 4E 4B 5F 59 4C 5F 4C 45 44 00 50 47 5F 33 56 33 5F 4D 43 49 4F 00 51 53 46 50 31 5F 41 43 54 5F 4C 45 44 00 51 53 46 50 31 5F 4C 4E 4B 5F 47 52 5F 4C 45 44 00 51 53 46 50 31 5F 4C 4E 4B 5F 59 4C 5F 4C 45 44 00 00 51 53 46 50 32 5F 41 43 54 5F 4C 45 44 00 51 53 46 50 32 5F 4C 4E 4B 5F 47 52 5F 4C 45 44 00 51 53 46 50 32 5F 4C 4E 4B 5F 59 4C 5F 4C 45 44 00 50 47 5F 31 32 56 5F 41 55 58 32 00 50 43 49 45 5F 45 58 50 31 5F 50 45 52 53 54 42 00 50 43 49 45 5F 45 58 50 32 5F 50 45 52 53 54 42 00 50 43 49 45 5F 45 58 50 33 5F 50 45 52 53 54 42 00 4D 43 49 4F 5F 50 32 5F 46 4C 45 58 49 4F 30 5F 42 55 46 00 50 4D 43 5F 55 41 52 54 31 5F 54 58 44 00 50 4D 43 5F 55 41 52 54 31 5F 52 58 44 00 50 43 49 45 5F 45 58 50 31 5F 43 50 52 53 4E 54 42 00 50 43 49 45 5F 45 58 50 32 5F 43 50 52 53 4E 54 42 00 50 43 49 45 5F 45 58 50 33 5F 43 50 52 53 4E 54 42 00 55 53 42 5F 50 52 45 53 00 00 00 00 00 00 00 00 00 00 00 00 00 00 00 00 00 00 00 00 00 00 00 00 00 00 00 00 00 00 00 00 00 00 00 00 00 00 00 00 00 00 00 00 00 00 00 00 00 00 00 00 00 00 00 00 00 00 00 00 00 00 00 00 00];
                        phandle = <0x2b>;
                };

                i2c0: i2c@ff020000 {
                        compatible = "cdns,i2c-r1p14";
                        status = "okay";
                        reg = <0x0 0xff020000 0x0 0x1000>;
                        interrupts = <0x0 0xe 0x4>;
                        interrupt-parent = <&imux>;
                        clock-frequency = <0x186a0>;
                        #address-cells = <0x1>;
                        #size-cells = <0x0>;
                        clocks = <&versal_clk 0x62>;
                        power-domains = <&versal_firmware 0x1822401d>;
                        xlnx,clock-freq = <0x5f5e0a4>;
                        xlnx,i2c-clk-freq-hz = <0x5f5e0a4>;
                        xlnx,ip-name = "psv_i2c";
                        xlnx,iic-board-interface = "custom";
                        xlnx,name = "versal_cips_0_pspmc_0_psv_i2c_0";
                        phandle = <0x54>;

                        regulator_u50: regulator@60 {
                                compatible = "isil,isl68224";
                                reg = <0x60>;
                                phandle = <0xb7>;
                        };

                        regulator_uXX: regulator@61 {
                                compatible = "isil,isl68224";
                                reg = <0x61>;
                                phandle = <0xb8>;
                        };

                        sensor_u30: temp-sensor@1a {
                                compatible = "onnn,cat34ts02", "jedec,jc-42.4-temp";
                                reg = <0x1a>;
                                phandle = <0xb9>;
                        };

                        gpio_u43: gpio@20 {
                                compatible = "ti,tca6416";
                                reg = <0x20>;
                                gpio-controller;
                                #gpio-cells = <0x2>;
                                interrupt-parent = <&gpio0>;
                                interrupts = <0x5 0x1>;
                                gpio-line-names = "TCRITn", "EN_VCC_FUSE", "FRU_EEPRM_WP", "PCIE_SMB_LT_EN", "IOEXP_POR_B", "CG_CONFI_GPIO0", "EN_DIMM", "DMB_PRSNT_B", "12V_AUX1_SENSE0_N", "12V_AUX1_SENSE1_N", "12V_AUX2_SENSE0_N", "12V_AUX2_SENSE1_N", "PG_3V3_QSFP", "DIMM_PWRGD", "BRD_PWRGD", "HBM_PWRGD";
                                phandle = <0xba>;
                        };

                        ina_u48: power-sensor@40 {
                                compatible = "ti,ina3221";
                                reg = <0x40>;
                                #address-cells = <0x1>;
                                #size-cells = <0x0>;
                                phandle = <0xbb>;

                                input@0 {
                                        reg = <0x0>;
                                        label = "VR_12V";
                                        shunt-resistor-micro-ohms = <0x7d0>;
                                };

                                input@1 {
                                        reg = <0x1>;
                                        label = "VR_3V3";
                                        shunt-resistor-micro-ohms = <0x7d0>;
                                };

                                input@2 {
                                        reg = <0x2>;
                                        label = "VR_3V3_QSFP";
                                        shunt-resistor-micro-ohms = <0x7d0>;
                                };
                        };

                        ina_u49: power-sensor@41 {
                                compatible = "ti,ina3221";
                                reg = <0x41>;
                                #address-cells = <0x1>;
                                #size-cells = <0x0>;
                                phandle = <0xbc>;

                                input@0 {
                                        reg = <0x0>;
                                        label = "VR_1V2_VCCO_DIMM";
                                        shunt-resistor-micro-ohms = <0x7d0>;
                                };

                                input@1 {
                                        reg = <0x1>;
                                        label = "VR_12V_AUX1";
                                        shunt-resistor-micro-ohms = <0x7d0>;
                                };

                                input@2 {
                                        reg = <0x2>;
                                        label = "VR_12V_AUX2";
                                        shunt-resistor-micro-ohms = <0x7d0>;
                                };
                        };
                };

                i2c1: i2c@ff030000 {
                        compatible = "cdns,i2c-r1p14";
                        status = "okay";
                        reg = <0x0 0xff030000 0x0 0x1000>;
                        interrupts = <0x0 0xf 0x4>;
                        interrupt-parent = <&imux>;
                        clock-frequency = <0x186a0>;
                        #address-cells = <0x1>;
                        #size-cells = <0x0>;
                        clocks = <&versal_clk 0x63>;
                        power-domains = <&versal_firmware 0x1822401e>;
                        xlnx,clock-freq = <0x5f5e0a4>;
                        xlnx,i2c-clk-freq-hz = <0x5f5e0a4>;
                        xlnx,ip-name = "psv_i2c";
                        xlnx,iic-board-interface = "custom";
                        xlnx,name = "versal_cips_0_pspmc_0_psv_i2c_1";
                        phandle = <0x55>;

                        qsfp_power: gpio@21 {
                                compatible = "ti,tca6408";
                                reg = <0x21>;
                                gpio-controller;
                                #gpio-cells = <0x2>;
                                interrupt-parent = <&gpio0>;
                                interrupts = <0xe 0x1>;
                                gpio-line-names = "EN_3V3_QSFP1", "EN_3V3_QSFP2", "EN_3V3_QSFP3", "EN_3V3_QSFP4", "PG_3V3_QSFP1", "PG_3V3_QSFP2", "PG_3V3_QSFP3", "PG_3V3_QSFP4";
                                phandle = <0xbd>;
                        };

                        i2c_qsfp1: i2c-mux@70 {
                                compatible = "nxp,pca9545";
                                #address-cells = <0x1>;
                                #size-cells = <0x0>;
                                #interrupt-cells = <0x2>;
                                reg = <0x70>;
                                interrupt-parent = <&gpio0>;
                                interrupts = <0xe 0x1>;
                                interrupt-controller;
                                phandle = <0x99>;

                                i2c@0 {
                                        #address-cells = <0x1>;
                                        #size-cells = <0x0>;
                                        reg = <0x0>;

                                        qsfp1: gpio@20 {
                                                compatible = "ti,tca6408";
                                                reg = <0x20>;
                                                gpio-controller;
                                                #gpio-cells = <0x2>;
                                                interrupt-parent = <&i2c_qsfp1>;
                                                interrupts = <0x2 0x1>;
                                                gpio-line-names = "QSFP1_MODSELL", "QSFP1_RESETL", "QSFP1_LPMODE", "QSFP1_MODPRSL", "QSFP1_INTR_B", "", "", "";
                                                phandle = <0xbe>;
                                        };
                                };

                                i2c@1 {
                                        #address-cells = <0x1>;
                                        #size-cells = <0x0>;
                                        reg = <0x1>;
                                };

                                i2c@2 {
                                        #address-cells = <0x1>;
                                        #size-cells = <0x0>;
                                        reg = <0x2>;

                                        qsfp2: gpio@20 {
                                                compatible = "ti,tca6408";
                                                reg = <0x20>;
                                                gpio-controller;
                                                #gpio-cells = <0x2>;
                                                interrupt-parent = <&i2c_qsfp1>;
                                                interrupts = <0x2 0x1>;
                                                gpio-line-names = "QSFP2_MODSELL", "QSFP2_RESETL", "QSFP2_LPMODE", "QSFP2_MODPRSL", "QSFP2_INTR_B", "", "", "";
                                                phandle = <0xbf>;
                                        };
                                };

                                i2c@3 {
                                        #address-cells = <0x1>;
                                        #size-cells = <0x0>;
                                        reg = <0x3>;
                                };
                        };

                        i2c_qsfp3: i2c-mux@71 {
                                compatible = "nxp,pca9545";
                                #address-cells = <0x1>;
                                #size-cells = <0x0>;
                                #interrupt-cells = <0x2>;
                                reg = <0x70>;
                                interrupt-parent = <&gpio0>;
                                interrupts = <0xe 0x1>;
                                interrupt-controller;
                                phandle = <0x9a>;

                                i2c@0 {
                                        #address-cells = <0x1>;
                                        #size-cells = <0x0>;
                                        reg = <0x0>;

                                        qsfp3: gpio@20 {
                                                compatible = "ti,tca6408";
                                                reg = <0x20>;
                                                gpio-controller;
                                                #gpio-cells = <0x2>;
                                                interrupt-parent = <&i2c_qsfp3>;
                                                interrupts = <0x2 0x1>;
                                                gpio-line-names = "QSFP3_MODSELL", "QSFP3_RESETL", "QSFP3_LPMODE", "QSFP3_MODPRSL", "QSFP3_INTR_B", "", "", "";
                                                phandle = <0xc0>;
                                        };
                                };

                                i2c@1 {
                                        #address-cells = <0x1>;
                                        #size-cells = <0x0>;
                                        reg = <0x1>;
                                };

                                i2c@2 {
                                        #address-cells = <0x1>;
                                        #size-cells = <0x0>;
                                        reg = <0x2>;

                                        qsfp4: gpio@20 {
                                                compatible = "ti,tca6408";
                                                reg = <0x20>;
                                                gpio-controller;
                                                #gpio-cells = <0x2>;
                                                interrupt-parent = <&i2c_qsfp3>;
                                                interrupts = <0x2 0x1>;
                                                gpio-line-names = "QSFP4_MODSELL", "QSFP4_RESETL", "QSFP4_LPMODE", "QSFP4_MODPRSL", "QSFP4_INTR_B", "", "", "";
                                                phandle = <0xc1>;
                                        };
                                };

                                i2c@3 {
                                        #address-cells = <0x1>;
                                        #size-cells = <0x0>;
                                        reg = <0x3>;
                                };
                        };

                        pcie: i2c-mux@72 {
                                compatible = "nxp,pca9545";
                                #address-cells = <0x1>;
                                #size-cells = <0x0>;
                                #interrupt-cells = <0x2>;
                                reg = <0x72>;
                                interrupt-parent = <&gpio0>;
                                interrupts = <0xe 0x1>;
                                interrupt-controller;
                                phandle = <0xc2>;
                        };
                };

                ocm: memory-controller@ff960000 {
                        compatible = "xlnx,zynqmp-ocmc-1.0";
                        reg = <0x0 0xff960000 0x0 0x1000>;
                        interrupts = <0x0 0xa 0x4>;
                        interrupt-parent = <&imux>;
                        phandle = <0xc8>;
                };

                rtc: rtc@f12a0000 {
                        compatible = "xlnx,zynqmp-rtc";
                        status = "okay";
                        reg = <0x0 0xf12a0000 0x0 0x100>;
                        interrupt-names = "alarm", "sec";
                        interrupts = <0x0 0x8e 0x4 0x0 0x8f 0x4>;
                        interrupt-parent = <&imux>;
                        calibration = <0x7fff>;
                        power-domains = <&versal_firmware 0x18224034>;
                        xlnx,ip-name = "psv_pmc_rtc";
                        xlnx,name = "versal_cips_0_pspmc_0_psv_pmc_rtc_0";
                        phandle = <0x3c>;
                };

                sdhci0: mmc@f1040000 {
                        compatible = "xlnx,versal-8.9a", "arasan,sdhci-8.9a";
                        status = "okay";
                        reg = <0x0 0xf1040000 0x0 0x10000>;
                        interrupts = <0x0 0x7e 0x4>;
                        interrupt-parent = <&imux>;
                        clock-names = "clk_xin", "clk_ahb", "gate";
                        #clock-cells = <0x1>;
                        clock-output-names = "clk_out_sd0", "clk_in_sd0";
                        clocks = <&versal_clk 0x3b>,
                         <&versal_clk 0x52>,
                         <&versal_clk 0x4a>;
                        power-domains = <&versal_firmware 0x1822402e>;
                        xlnx,sd-board-interface = "custom";
                        xlnx,is-cache-coherent = <0x0>;
                        xlnx,clk-50-ddr-otap-dly = <0x5>;
                        xlnx,clk-50-sdr-itap-dly = <0x2c>;
                        xlnx,has-emio = <0x0>;
                        clock-frequency = <0xbebc149>;
                        xlnx,clk-100-sdr-otap-dly = <0x0>;
                        xlnx,mio-bank = <0x0>;
                        xlnx,ip-name = "psv_pmc_sd";
                        xlnx,bus-width = <0x8>;
                        xlnx,card-detect = <0x0>;
                        xlnx,has-wp = <0x0>;
                        xlnx,has-cd = <0x0>;
                        xlnx,slot-type = <0x1>;
                        xlnx,clk-50-sdr-otap-dly = <0x5>;
                        xlnx,clk-50-ddr-itap-dly = <0x1e>;
                        xlnx,has-power = <0x0>;
                        xlnx,clk-200-sdr-otap-dly = <0x2>;
                        xlnx,sdio-clk-freq-hz = <0xbebc149>;
                        xlnx,write-protect = <0x0>;
                        xlnx,name = "versal_cips_0_pspmc_0_psv_pmc_sd_0";
                        non-removable;
                        disable-wp;
                        no-sd;
                        no-sdio;
                        cap-mmc-hw-reset;
                        bus-width = <0x8>;
                        phandle = <0x2c>;
                };

                serial0: serial@ff000000 {
                        compatible = "arm,pl011", "arm,primecell";
                        status = "okay";
                        reg = <0x0 0xff000000 0x0 0x1000>;
                        interrupts = <0x0 0x12 0x4>;
                        interrupt-parent = <&imux>;
                        reg-io-width = <0x4>;
                        clock-names = "uartclk", "apb_pclk";
                        bootph-all;
                        clocks = <&versal_clk 0x5c>,
                         <&versal_clk 0x52>;
                        power-domains = <&versal_firmware 0x18224021>;
                        xlnx,clock-freq = <0x5f5e0a4>;
                        u-boot,dm-pre-reloc;
                        xlnx,uart-board-interface = "custom";
                        xlnx,has-modem = <0x0>;
                        xlnx,ip-name = "psv_sbsauart";
                        xlnx,baudrate = <0x1c200>;
                        cts-override;
                        port-number = <0x0>;
                        xlnx,uart-clk-freq-hz = <0x5f5e0a4>;
                        xlnx,name = "versal_cips_0_pspmc_0_psv_sbsauart_0";
                        phandle = <0x52>;
                };

                serial1: serial@ff010000 {
                        compatible = "arm,pl011", "arm,primecell";
                        status = "okay";
                        reg = <0x0 0xff010000 0x0 0x1000>;
                        interrupts = <0x0 0x13 0x4>;
                        interrupt-parent = <&imux>;
                        reg-io-width = <0x4>;
                        clock-names = "uartclk", "apb_pclk";
                        bootph-all;
                        clocks = <&versal_clk 0x5d>,
                         <&versal_clk 0x52>;
                        power-domains = <&versal_firmware 0x18224022>;
                        xlnx,clock-freq = <0x5f5e0a4>;
                        u-boot,dm-pre-reloc;
                        xlnx,uart-board-interface = "custom";
                        xlnx,has-modem = <0x0>;
                        xlnx,ip-name = "psv_sbsauart";
                        xlnx,baudrate = <0x1c200>;
                        cts-override;
                        port-number = <0x0>;
                        xlnx,uart-clk-freq-hz = <0x5f5e0a4>;
                        xlnx,name = "versal_cips_0_pspmc_0_psv_sbsauart_1";
                        phandle = <0x53>;
                };

                smmu: iommu@fd800000 {
                        compatible = "arm,mmu-500";
                        status = "okay";
                        reg = <0x0 0xfd800000 0x0 0x40000>;
                        stream-match-mask = <0x7c00>;
                        #iommu-cells = <0x1>;
                        #global-interrupts = <0x1>;
                        interrupts = <0x0 0x6b 0x4 0x0 0x6b 0x4 0x0 0x6b 0x4 0x0 0x6b 0x4 0x0 0x6b 0x4 0x0 0x6b 0x4 0x0 0x6b 0x4 0x0 0x6b 0x4 0x0 0x6b 0x4 0x0 0x6b 0x4 0x0 0x6b 0x4 0x0 0x6b 0x4 0x0 0x6b 0x4 0x0 0x6b 0x4 0x0 0x6b 0x4 0x0 0x6b 0x4 0x0 0x6b 0x4 0x0 0x6b 0x4 0x0 0x6b 0x4 0x0 0x6b 0x4 0x0 0x6b 0x4 0x0 0x6b 0x4 0x0 0x6b 0x4 0x0 0x6b 0x4 0x0 0x6b 0x4 0x0 0x6b 0x4 0x0 0x6b 0x4 0x0 0x6b 0x4 0x0 0x6b 0x4 0x0 0x6b 0x4 0x0 0x6b 0x4 0x0 0x6b 0x4 0x0 0x6b 0x4>;
                        interrupt-parent = <&imux>;
                        xlnx,ip-name = "psv_fpd_smmutcu";
                        xlnx,name = "versal_cips_0_pspmc_0_psv_fpd_smmutcu_0";
                        phandle = <0x51>;
                };

                ospi: spi@f1010000 {
                        compatible = "xlnx,versal-ospi-1.0", "cdns,qspi-nor";
                        status = "okay";
                        reg = <0x0 0xf1010000 0x0 0x10000 0x0 0xc0000000 0x0 0x20000000>;
                        interrupts = <0x0 0x7c 0x4>;
                        interrupt-parent = <&imux>;
                        cdns,fifo-depth = <0x100>;
                        cdns,fifo-width = <0x4>;
                        cdns,is-dma = <0x1>;
                        cdns,trigger-address = <0xc0000000>;
                        #address-cells = <0x1>;
                        #size-cells = <0x0>;
                        clocks = <&versal_clk 0x3a>;
                        power-domains = <&versal_firmware 0x1822402a>;
                        reset-names = "qspi";
                        resets = <&versal_reset 0xc10402e>;
                        is-stacked = <0x0>;
                        xlnx,is-cache-coherent = <0x0>;
                        xlnx,clock-freq = <0xbebc149>;
                        xlnx,ip-name = "psv_pmc_ospi";
                        xlnx,ospi-clk-freq-hz = <0xbebc149>;
                        is-dual = <0x0>;
                        xlnx,ospi-mode = <0x0>;
                        xlnx,name = "versal_cips_0_pspmc_0_psv_pmc_ospi_0";
                        bus-num = <0x2>;
                        num-cs = <0x1>;
                        phandle = <0x2a>;

                        ospi_flash: flash@0 {
                                compatible = "mt35xu02g", "micron,m25p80", "jedec,spi-nor";
                                reg = <0x0>;
                                #address-cells = <0x1>;
                                #size-cells = <0x1>;
                                cdns,read-delay = <0x0>;
                                cdns,tshsl-ns = <0x0>;
                                cdns,tsd2d-ns = <0x0>;
                                cdns,tchsh-ns = <0x1>;
                                cdns,tslch-ns = <0x1>;
                                spi-tx-bus-width = <0x8>;
                                spi-rx-bus-width = <0x8>;
                                spi-max-frequency = <0x1312d00>;
                                no-wp;
                                reset-gpios = <&gpio1 0xc 0x1>;
                                phandle = <0xca>;

                                partition@0 {
                                        label = "spi0-flash0";
                                        reg = <0x0 0x8000000>;
                                };
                        };
                };

                spi0: spi@ff040000 {
                        compatible = "cdns,spi-r1p6";
                        status = "okay";
                        reg = <0x0 0xff040000 0x0 0x1000>;
                        interrupts = <0x0 0x10 0x4>;
                        interrupt-parent = <&imux>;
                        clock-names = "ref_clk", "pclk";
                        #address-cells = <0x1>;
                        #size-cells = <0x0>;
                        clocks = <&versal_clk 0x5e>,
                         <&versal_clk 0x52>;
                        power-domains = <&versal_firmware 0x1822401b>;
                        xlnx,spi-board-interface = "custom";
                        xlnx,has-ss0 = <0x1>;
                        xlnx,ip-name = "psv_spi";
                        xlnx,has-ss1 = <0x0>;
                        num-cs = <0x1>;
                        xlnx,spi-clk-freq-hz = <0xbebc149>;
                        xlnx,has-ss2 = <0x0>;
                        xlnx,name = "versal_cips_0_pspmc_0_psv_spi_0";
                        phandle = <0x56>;

                        flash@0 {
                                compatible = "jedec,spi-nor";
                                spi-max-frequency = <0x7ed6b40>;
                                reg = <0x0>;
                        };
                };

                sysmon0: sysmon@f1270000 {
                        compatible = "xlnx,versal-sysmon";
                        #io-channel-cells = <0x0>;
                        reg = <0x0 0xf1270000 0x0 0x4000>;
                        interrupts = <0x0 0x90 0x4>;
                        xlnx,numchannels = "";
                        #address-cells = <0x2>;
                        #size-cells = <0x2>;
                        xlnx,nodeid = <0x18224055>;
                        xlnx,sat-63-desc = "PS , FPD , satellite";
                        xlnx,sat-17-x = <0x35e5>;
                        xlnx,sat-1-desc = "PMC , system , ADC";
                        xlnx,sat-9-x = <0x6ed4>;
                        xlnx,sat-17-y = <0x676f>;
                        xlnx,sat-19-desc = "VNOC , satellite";
                        xlnx,sat-20-desc = "HBM , Satellite , (right)";
                        xlnx,sat-9-y = <0x772d>;
                        xlnx,sat-22-x = <0x21a7>;
                        xlnx,ip-name = "psv_pmc_sysmon";
                        xlnx,sat-22-y = <0x7362>;
                        xlnx,sat-16-desc = "HBM , Satellite , (left)";
                        xlnx,sat-9-desc = "Clocking , column , satellite";
                        xlnx,sat-26-x = <0xf56>;
                        xlnx,sat-28-desc = "Clocking , column , satellite";
                        xlnx,sat-26-y = <0x7cf2>;
                        xlnx,sat-10-x = <0x6ed4>;
                        xlnx,sat-64-x = <0x56b>;
                        xlnx,sat-2-x = <0x56b>;
                        xlnx,sat-10-y = <0x70fe>;
                        xlnx,sat-64-y = <0xf11>;
                        xlnx,sat-2-y = <0x649d>;
                        xlnx,sat-13-desc = "VNOC , satellite";
                        xlnx,sat-6-desc = "HBM , Satellite , (right)";
                        xlnx,sat-14-x = <0x4a23>;
                        xlnx,sat-6-x = <0x5f7a>;
                        xlnx,sat-25-desc = "Clocking , column , satellite";
                        xlnx,sat-14-y = <0x7362>;
                        xlnx,sat-6-y = <0x9780>;
                        xlnx,sat-10-desc = "Clocking , column , satellite";
                        xlnx,sat-18-x = <0x35e5>;
                        xlnx,sat-3-desc = "VNOC , satellite";
                        xlnx,sat-18-y = <0x7362>;
                        xlnx,sat-22-desc = "VNOC , satellite";
                        xlnx,sat-23-x = <0x21a7>;
                        xlnx,sat-23-y = <0x7f56>;
                        xlnx,sat-18-desc = "VNOC , satellite";
                        xlnx,sat-27-x = <0xf56>;
                        xlnx,sat-27-y = <0x772d>;
                        xlnx,sat-11-x = <0x6ed4>;
                        xlnx,sat-3-x = <0x5e61>;
                        xlnx,sat-11-y = <0x6b39>;
                        xlnx,sat-3-y = <0x676f>;
                        status = "okay";
                        xlnx,sat-15-desc = "VNOC , satellite";
                        xlnx,sat-15-x = <0x4a23>;
                        xlnx,sat-8-desc = "Clocking , column , satellite";
                        xlnx,sat-7-x = <0x6ed4>;
                        xlnx,name = "versal_cips_0_pspmc_0_psv_pmc_sysmon_0";
                        xlnx,sat-15-y = <0x7f56>;
                        xlnx,sat-7-y = <0x8321>;
                        xlnx,sat-27-desc = "Clocking , column , satellite";
                        xlnx,sat-12-desc = "Clocking , column , satellite";
                        xlnx,sat-19-x = <0x35e5>;
                        xlnx,sat-20-x = <0x3441>;
                        xlnx,sat-19-y = <0x7f56>;
                        xlnx,sat-20-y = <0x9780>;
                        xlnx,sat-5-desc = "VNOC , satellite";
                        xlnx,sat-24-desc = "HBM , Satellite , (left)";
                        xlnx,sat-24-x = <0x1ea8>;
                        xlnx,sat-24-y = <0x9780>;
                        xlnx,sat-64-desc = "PS , LPD , satellite";
                        xlnx,sat-2-desc = "PMC , user , ADC";
                        xlnx,sat-28-x = <0xf56>;
                        xlnx,sat-21-desc = "VNOC , satellite";
                        xlnx,sat-28-y = <0x70fe>;
                        xlnx,sat-12-x = <0x6ed4>;
                        xlnx,sat-4-x = <0x5e61>;
                        xlnx,sat-12-y = <0x650b>;
                        xlnx,sat-4-y = <0x7362>;
                        xlnx,sat-16-x = <0x49e0>;
                        xlnx,sat-17-desc = "VNOC , satellite";
                        xlnx,sat-8-x = <0x6ed4>;
                        xlnx,sat-16-y = <0x9780>;
                        xlnx,sat-8-y = <0x7cf2>;
                        xlnx,sat-21-x = <0x21a7>;
                        xlnx,sat-14-desc = "VNOC , satellite";
                        xlnx,sat-21-y = <0x676f>;
                        xlnx,sat-7-desc = "Clocking , column , satellite";
                        xlnx,sat-26-desc = "Clocking , column , satellite";
                        xlnx,sat-25-x = <0xf56>;
                        xlnx,sat-25-y = <0x8321>;
                        xlnx,sat-63-x = <0x56b>;
                        xlnx,sat-11-desc = "Clocking , column , satellite";
                        xlnx,sat-1-x = <0x56b>;
                        xlnx,sat-63-y = <0xf11>;
                        xlnx,sat-1-y = <0x649d>;
                        xlnx,sat-4-desc = "VNOC , satellite";
                        xlnx,sat-13-x = <0x4a23>;
                        xlnx,sat-23-desc = "VNOC , satellite";
                        xlnx,sat-5-x = <0x5e61>;
                        xlnx,sat-13-y = <0x676f>;
                        xlnx,sat-5-y = <0x7f56>;
                        phandle = <0x3b>;
                };

                ttc0: timer@ff0e0000 {
                        compatible = "cdns,ttc";
                        status = "okay";
                        interrupts = <0x0 0x25 0x4 0x0 0x26 0x4 0x0 0x27 0x4>;
                        interrupt-parent = <&imux>;
                        reg = <0x0 0xff0e0000 0x0 0x1000>;
                        timer-width = <0x20>;
                        clocks = <&versal_clk 0x27>;
                        power-domains = <&versal_firmware 0x18224024>;
                        xlnx,ttc-board-interface = "custom";
                        xlnx,ttc-clk2-freq-hz = <0x8f0d0f7>;
                        xlnx,ttc-clk1-clksrc = <0x0>;
                        xlnx,clock-freq = <0x8f0d0f7>;
                        xlnx,ttc-clk2-clksrc = <0x0>;
                        xlnx,ip-name = "psv_ttc";
                        xlnx,ttc-clk0-freq-hz = <0x8f0d0f7>;
                        xlnx,ttc-clk1-freq-hz = <0x8f0d0f7>;
                        xlnx,ttc-clk0-clksrc = <0x0>;
                        xlnx,name = "versal_cips_0_pspmc_0_psv_ttc_0";
                        phandle = <0x5a>;
                };

                ttc1: timer@ff0f0000 {
                        compatible = "cdns,ttc";
                        status = "okay";
                        interrupts = <0x0 0x28 0x4 0x0 0x29 0x4 0x0 0x2a 0x4>;
                        interrupt-parent = <&imux>;
                        reg = <0x0 0xff0f0000 0x0 0x1000>;
                        timer-width = <0x20>;
                        clocks = <&versal_clk 0x28>;
                        power-domains = <&versal_firmware 0x18224025>;
                        xlnx,ttc-board-interface = "custom";
                        xlnx,ttc-clk2-freq-hz = <0x8f0d0f7>;
                        xlnx,ttc-clk1-clksrc = <0x0>;
                        xlnx,clock-freq = <0x8f0d0f7>;
                        xlnx,ttc-clk2-clksrc = <0x0>;
                        xlnx,ip-name = "psv_ttc";
                        xlnx,ttc-clk0-freq-hz = <0x8f0d0f7>;
                        xlnx,ttc-clk1-freq-hz = <0x8f0d0f7>;
                        xlnx,ttc-clk0-clksrc = <0x0>;
                        xlnx,name = "versal_cips_0_pspmc_0_psv_ttc_1";
                        phandle = <0x5b>;
                };

                ttc2: timer@ff100000 {
                        compatible = "cdns,ttc";
                        status = "okay";
                        interrupts = <0x0 0x2b 0x4 0x0 0x2c 0x4 0x0 0x2d 0x4>;
                        interrupt-parent = <&imux>;
                        reg = <0x0 0xff100000 0x0 0x1000>;
                        timer-width = <0x20>;
                        clocks = <&versal_clk 0x29>;
                        power-domains = <&versal_firmware 0x18224026>;
                        xlnx,ttc-board-interface = "custom";
                        xlnx,ttc-clk2-freq-hz = <0x8f0d0f7>;
                        xlnx,ttc-clk1-clksrc = <0x0>;
                        xlnx,clock-freq = <0x8f0d0f7>;
                        xlnx,ttc-clk2-clksrc = <0x0>;
                        xlnx,ip-name = "psv_ttc";
                        xlnx,ttc-clk0-freq-hz = <0x8f0d0f7>;
                        xlnx,ttc-clk1-freq-hz = <0x8f0d0f7>;
                        xlnx,ttc-clk0-clksrc = <0x0>;
                        xlnx,name = "versal_cips_0_pspmc_0_psv_ttc_2";
                        phandle = <0x5c>;
                };

                ttc3: timer@ff110000 {
                        compatible = "cdns,ttc";
                        status = "okay";
                        interrupts = <0x0 0x2e 0x4 0x0 0x2f 0x4 0x0 0x30 0x4>;
                        interrupt-parent = <&imux>;
                        reg = <0x0 0xff110000 0x0 0x1000>;
                        timer-width = <0x20>;
                        clocks = <&versal_clk 0x2a>;
                        power-domains = <&versal_firmware 0x18224027>;
                        xlnx,ttc-board-interface = "custom";
                        xlnx,ttc-clk2-freq-hz = <0x8f0d0f7>;
                        xlnx,ttc-clk1-clksrc = <0x0>;
                        xlnx,clock-freq = <0x8f0d0f7>;
                        xlnx,ttc-clk2-clksrc = <0x0>;
                        xlnx,ip-name = "psv_ttc";
                        xlnx,ttc-clk0-freq-hz = <0x8f0d0f7>;
                        xlnx,ttc-clk1-freq-hz = <0x8f0d0f7>;
                        xlnx,ttc-clk0-clksrc = <0x0>;
                        xlnx,name = "versal_cips_0_pspmc_0_psv_ttc_3";
                        phandle = <0x5d>;
                };

                dma0: pmcdma@f11c0000 {
                        status = "okay";
                        compatible = "xlnx,zynqmp-csudma-1.0";
                        interrupt-parent = <&imux>;
                        interrupts = <0x0 0x83 0x4>;
                        reg = <0x0 0xf11c0000 0x0 0x10000>;
                        xlnx,dma-type = <0x1>;
                        xlnx,ip-name = "psv_pmc_dma";
                        xlnx,name = "versal_cips_0_pspmc_0_psv_pmc_dma_0";
                        phandle = <0x30>;
                };

                dma1: pmcdma@f11d0000 {
                        status = "okay";
                        compatible = "xlnx,zynqmp-csudma-1.0";
                        interrupt-parent = <&imux>;
                        interrupts = <0x0 0x84 0x4>;
                        reg = <0x0 0xf11d0000 0x0 0x10000>;
                        xlnx,dma-type = <0x2>;
                        xlnx,ip-name = "psv_pmc_dma";
                        xlnx,name = "versal_cips_0_pspmc_0_psv_pmc_dma_1";
                        phandle = <0x31>;
                };

                pmc_trng: pmc_trng@f1230000 {
                        compatible = "xlnx,psv-pmc-trng-1.0";
                        status = "okay";
                        reg = <0x0 0xf1230000 0x0 0x10000>;
                        xlnx,device-id = <0x0>;
                        xlnx,ip-name = "psv_pmc_trng";
                        xlnx,name = "versal_cips_0_pspmc_0_psv_pmc_trng";
                        phandle = <0x37>;
                };

                pmc_cfi_cframe_0: cframe@f12d0000 {
                        compatible = "xlnx,psv-pmc-cfi-cframe-1.0";
                        status = "okay";
                        reg = <0x0 0xf12d0000 0x0 0x1000>;
                        xlnx,ip-name = "psv_pmc_cfi_cframe";
                        xlnx,name = "versal_cips_0_pspmc_0_psv_pmc_cfi_cframe_0";
                        phandle = <0x3e>;
                };

                pmc_cfu_apb_0: cfu_apb@f12b0000 {
                        compatible = "xlnx,psv-pmc-cfu-apb-1.0";
                        status = "okay";
                        reg = <0x0 0xf12b0000 0x0 0x10000>;
                        xlnx,ip-name = "psv_pmc_cfu_apb";
                        xlnx,name = "versal_cips_0_pspmc_0_psv_pmc_cfu_apb_0";
                        phandle = <0x3d>;
                };

                pmc_ppu1_mdm_0: ppu1_mdm@f0310000 {
                        compatible = "xlnx,psv-pmc-ppu1-mdm-1.0";
                        status = "okay";
                        reg = <0x0 0xf0310000 0x0 0x8000>;
                        xlnx,ip-name = "psv_pmc_ppu1_mdm";
                        xlnx,name = "versal_cips_0_pspmc_0_psv_pmc_ppu1_mdm_0";
                        phandle = <0x9>;
                };

                iomodule0: iomodule@f0280000 {
                        status = "okay";
                        compatible = "xlnx,iomodule-3.1";
                        reg = <0x0 0xf0280000 0x0 0x1000 0xffffffff 0xffffffff 0x0 0xe0000>;
                        xlnx,intc-has-fast = <0x0>;
                        xlnx,intc-base-vectors = <0xf0240000>;
                        xlnx,intc-addr-width = <0x20>;
                        xlnx,intc-level-edge = <0x7fff>;
                        xlnx,clock-freq = <0x5f5e100>;
                        xlnx,uart-baudrate = <0x1c200>;
                        xlnx,pit-used = <0x1 0x1 0x1 0x1>;
                        xlnx,pit-size = <0x20 0x20 0x20 0x20>;
                        xlnx,pit-mask = <0xffffffff 0xffffffff 0xffffffff 0xffffffff>;
                        xlnx,pit-prescaler = <0x9 0x0 0x9 0x0>;
                        xlnx,pit-readable = <0x1 0x1 0x1 0x1>;
                        xlnx,gpo-init = <0x0 0x0 0x0 0x0>;
                        xlnx,options = <0x1>;
                        xlnx,max-intr-size = <0x20>;
                        xlnx,gpo4-size = <0x20>;
                        xlnx,tmr = <0x0>;
                        xlnx,pit1-readable = <0x1>;
                        xlnx,mask = <0xfffff000>;
                        xlnx,pit2-prescaler = <0x0>;
                        xlnx,gpi3-interrupt = <0x0>;
                        xlnx,intc-positive = <0xffff>;
                        xlnx,ip-name = "iomodule";
                        xlnx,gpo1-size = <0x3>;
                        xlnx,pit3-size = <0x20>;
                        xlnx,fit3-interrupt = <0x0>;
                        xlnx,fit1-no-clocks = <0x1848>;
                        xlnx,gpi2-size = <0x20>;
                        xlnx,pit2-readable = <0x1>;
                        xlnx,intc-irq-connection = <0x0>;
                        xlnx,uart-tx-interrupt = <0x1>;
                        xlnx,use-config-reset = <0x0>;
                        xlnx,pit2-interrupt = <0x1>;
                        xlnx,gpo4-init = <0x0>;
                        xlnx,pit3-readable = <0x1>;
                        xlnx,pit3-prescaler = <0x9>;
                        xlnx,gpi4-interrupt = <0x0>;
                        xlnx,gpo1-init = <0x0>;
                        xlnx,use-io-bus = <0x0>;
                        xlnx,use-gpo1 = <0x1>;
                        xlnx,fit4-interrupt = <0x0>;
                        xlnx,gpo3-size = <0x20>;
                        xlnx,use-gpo2 = <0x0>;
                        xlnx,uart-data-bits = <0x8>;
                        xlnx,gpio1-board-interface = "Custom";
                        xlnx,use-gpo3 = <0x0>;
                        xlnx,fit2-no-clocks = <0x1848>;
                        xlnx,gpio2-board-interface = "Custom";
                        xlnx,use-gpo4 = <0x0>;
                        xlnx,gpi4-size = <0x20>;
                        xlnx,gpio3-board-interface = "Custom";
                        xlnx,uart-rx-interrupt = <0x1>;
                        xlnx,uart-error-interrupt = <0x1>;
                        xlnx,gpio4-board-interface = "Custom";
                        xlnx,pit4-readable = <0x1>;
                        xlnx,intc-use-irq-out = <0x0>;
                        xlnx,use-board-flow;
                        xlnx,pit2-size = <0x20>;
                        xlnx,intc-intr-size = <0x10>;
                        xlnx,intc-use-ext-intr = <0x1>;
                        xlnx,name = "versal_cips_0_pspmc_0_psv_pmc_iomodule_0";
                        xlnx,gpi1-size = <0x20>;
                        xlnx,edk-special = "INTR_CTRL";
                        xlnx,pit3-interrupt = <0x1>;
                        xlnx,use-gpi1 = <0x0>;
                        xlnx,gpi1-interrupt = <0x0>;
                        xlnx,use-gpi2 = <0x0>;
                        xlnx,use-gpi3 = <0x0>;
                        xlnx,use-gpi4 = <0x0>;
                        xlnx,fit1-interrupt = <0x0>;
                        xlnx,pit4-prescaler = <0x0>;
                        xlnx,gpo3-init = <0x0>;
                        xlnx,edk-iptype = "PERIPHERAL";
                        xlnx,fit3-no-clocks = <0x1848>;
                        xlnx,use-uart-rx = <0x1>;
                        xlnx,instance = "iomodule_0";
                        xlnx,uart-prog-baudrate = <0x1>;
                        xlnx,use-pit1 = <0x1>;
                        xlnx,gpo2-size = <0x20>;
                        xlnx,use-pit2 = <0x1>;
                        xlnx,pit4-size = <0x20>;
                        xlnx,use-pit3 = <0x1>;
                        xlnx,use-pit4 = <0x1>;
                        xlnx,pit4-interrupt = <0x1>;
                        xlnx,gpi3-size = <0x20>;
                        xlnx,intc-async-intr = <0xffff>;
                        xlnx,avoid-primitives = <0x0>;
                        xlnx,gpi2-interrupt = <0x0>;
                        xlnx,pit1-prescaler = <0x9>;
                        xlnx,use-tmr-disable = <0x0>;
                        xlnx,use-fit1 = <0x0>;
                        xlnx,pit1-size = <0x20>;
                        xlnx,intc-num-sync-ff = <0x2>;
                        xlnx,uart-board-interface = "rs232_uart";
                        xlnx,use-fit2 = <0x0>;
                        xlnx,fit2-interrupt = <0x0>;
                        xlnx,use-fit3 = <0x0>;
                        xlnx,use-fit4 = <0x0>;
                        xlnx,uart-use-parity = <0x0>;
                        xlnx,lmb-dwidth = <0x20>;
                        xlnx,fit4-no-clocks = <0x1848>;
                        xlnx,uart-odd-parity = <0x0>;
                        xlnx,freq = <0x5f5e100>;
                        xlnx,use-uart-tx = <0x1>;
                        xlnx,pit1-interrupt = <0x1>;
                        xlnx,gpo2-init = <0x0>;
                        xlnx,io-mask = <0xfffe0000>;
                        xlnx,lmb-awidth = <0x20>;
                        phandle = <0x7d>;
                };

                ipi_pmc: mailbox@ff320000 {
                        status = "okay";
                        compatible = "xlnx,zynqmp-ipi-mailbox";
                        interrupt-parent = <&imux>;
                        interrupts = <0x0 0x1b 0x4>;
                        reg = <0x0 0xff320000 0x0 0x20>;
                        xlnx,ipi-bitmask = <0x2>;
                        xlnx,ipi-id = <0x1>;
                        xlnx,ipi-buf-index = <0x1>;
                        #address-cells = <0x2>;
                        #size-cells = <0x2>;
                        ranges;
                        xlnx,cpu-name = "PMC";
                        xlnx,buffer-base = <0xff3f0200>;
                        xlnx,buffer-index = <0x1>;
                        xlnx,ip-name = "psv_ipi";
                        xlnx,ipi-target-count = <0xa>;
                        xlnx,int-id = <0x3b>;
                        xlnx,bit-position = <0x1>;
                        xlnx,name = "versal_cips_0_pspmc_0_psv_ipi_pmc";
                        phandle = <0x78>;

                        versal_cips_0_pspmc_0_psv_ipi_pmc_0: child@0 {
                                xlnx,ipi-bitmask = <0x4>;
                                xlnx,ipi-rsp-msg-buf = <0xff3f02a0>;
                                xlnx,ipi-id = <0x2>;
                                xlnx,ipi-buf-index = <0x2>;
                                xlnx,ipi-req-msg-buf = <0xff3f0280>;
                                phandle = <0xd7>;
                        };

                        versal_cips_0_pspmc_0_psv_ipi_pmc_1: child@1 {
                                xlnx,ipi-bitmask = <0x8>;
                                xlnx,ipi-rsp-msg-buf = <0xff3f02e0>;
                                xlnx,ipi-id = <0x3>;
                                xlnx,ipi-buf-index = <0x3>;
                                xlnx,ipi-req-msg-buf = <0xff3f02c0>;
                                phandle = <0xd8>;
                        };

                        versal_cips_0_pspmc_0_psv_ipi_pmc_2: child@2 {
                                xlnx,ipi-bitmask = <0x10>;
                                xlnx,ipi-rsp-msg-buf = <0xff3f0320>;
                                xlnx,ipi-id = <0x4>;
                                xlnx,ipi-buf-index = <0x4>;
                                xlnx,ipi-req-msg-buf = <0xff3f0300>;
                                phandle = <0xd9>;
                        };

                        versal_cips_0_pspmc_0_psv_ipi_pmc_3: child@3 {
                                xlnx,ipi-bitmask = <0x20>;
                                xlnx,ipi-rsp-msg-buf = <0xff3f0360>;
                                xlnx,ipi-id = <0x5>;
                                xlnx,ipi-buf-index = <0x5>;
                                xlnx,ipi-req-msg-buf = <0xff3f0340>;
                                phandle = <0xda>;
                        };

                        versal_cips_0_pspmc_0_psv_ipi_pmc_4: child@4 {
                                xlnx,ipi-bitmask = <0x40>;
                                xlnx,ipi-rsp-msg-buf = <0xff3f03a0>;
                                xlnx,ipi-id = <0x6>;
                                xlnx,ipi-buf-index = <0x6>;
                                xlnx,ipi-req-msg-buf = <0xff3f0380>;
                                phandle = <0xdb>;
                        };

                        versal_cips_0_pspmc_0_psv_ipi_pmc_5: child@5 {
                                xlnx,ipi-bitmask = <0x80>;
                                xlnx,ipi-rsp-msg-buf = <0xff3f03e0>;
                                xlnx,ipi-id = <0x7>;
                                xlnx,ipi-buf-index = <0x7>;
                                xlnx,ipi-req-msg-buf = <0xff3f03c0>;
                                phandle = <0xdc>;
                        };

                        versal_cips_0_pspmc_0_psv_ipi_pmc_6: child@6 {
                                xlnx,ipi-bitmask = <0x200>;
                                xlnx,ipi-id = <0x9>;
                                xlnx,ipi-buf-index = <0xffff>;
                                phandle = <0xdd>;
                        };

                        versal_cips_0_pspmc_0_psv_ipi_pmc_7: child@7 {
                                xlnx,ipi-bitmask = <0x2>;
                                xlnx,ipi-rsp-msg-buf = <0xff3f0260>;
                                xlnx,ipi-id = <0x1>;
                                xlnx,ipi-buf-index = <0x1>;
                                xlnx,ipi-req-msg-buf = <0xff3f0240>;
                                phandle = <0xde>;
                        };

                        versal_cips_0_pspmc_0_psv_ipi_pmc_8: child@8 {
                                xlnx,ipi-bitmask = <0x100>;
                                xlnx,ipi-id = <0x8>;
                                xlnx,ipi-buf-index = <0xffff>;
                                phandle = <0xdf>;
                        };

                        versal_cips_0_pspmc_0_psv_ipi_pmc_9: child@9 {
                                xlnx,ipi-bitmask = <0x1>;
                                xlnx,ipi-rsp-msg-buf = <0xff3f0220>;
                                xlnx,ipi-id = <0x0>;
                                xlnx,ipi-buf-index = <0x0>;
                                xlnx,ipi-req-msg-buf = <0xff3f0200>;
                                phandle = <0xe0>;
                        };
                };

                ipi_pmc_nobuf: mailbox@ff390000 {
                        status = "okay";
                        compatible = "xlnx,zynqmp-ipi-mailbox";
                        interrupt-parent = <&imux>;
                        interrupts = <0x0 0x1c 0x4>;
                        reg = <0x0 0xff390000 0x0 0x20>;
                        xlnx,ipi-bitmask = <0x100>;
                        xlnx,ipi-id = <0x8>;
                        xlnx,ipi-buf-index = <0xffff>;
                        #address-cells = <0x2>;
                        #size-cells = <0x2>;
                        ranges;
                        xlnx,cpu-name = "PMC";
                        xlnx,buffer-base = "NIL";
                        xlnx,buffer-index = "NIL";
                        xlnx,ip-name = "psv_ipi";
                        xlnx,ipi-target-count = <0xa>;
                        xlnx,int-id = <0x3c>;
                        xlnx,bit-position = <0x8>;
                        xlnx,name = "versal_cips_0_pspmc_0_psv_ipi_pmc_nobuf";
                        phandle = <0x79>;

                        versal_cips_0_pspmc_0_psv_ipi_pmc_nobuf_0: child@0 {
                                xlnx,ipi-bitmask = <0x4>;
                                xlnx,ipi-id = <0x2>;
                                xlnx,ipi-buf-index = <0x2>;
                                phandle = <0xe1>;
                        };

                        versal_cips_0_pspmc_0_psv_ipi_pmc_nobuf_1: child@1 {
                                xlnx,ipi-bitmask = <0x8>;
                                xlnx,ipi-id = <0x3>;
                                xlnx,ipi-buf-index = <0x3>;
                                phandle = <0xe2>;
                        };

                        versal_cips_0_pspmc_0_psv_ipi_pmc_nobuf_2: child@2 {
                                xlnx,ipi-bitmask = <0x10>;
                                xlnx,ipi-id = <0x4>;
                                xlnx,ipi-buf-index = <0x4>;
                                phandle = <0xe3>;
                        };

                        versal_cips_0_pspmc_0_psv_ipi_pmc_nobuf_3: child@3 {
                                xlnx,ipi-bitmask = <0x20>;
                                xlnx,ipi-id = <0x5>;
                                xlnx,ipi-buf-index = <0x5>;
                                phandle = <0xe4>;
                        };

                        versal_cips_0_pspmc_0_psv_ipi_pmc_nobuf_4: child@4 {
                                xlnx,ipi-bitmask = <0x40>;
                                xlnx,ipi-id = <0x6>;
                                xlnx,ipi-buf-index = <0x6>;
                                phandle = <0xe5>;
                        };

                        versal_cips_0_pspmc_0_psv_ipi_pmc_nobuf_5: child@5 {
                                xlnx,ipi-bitmask = <0x80>;
                                xlnx,ipi-id = <0x7>;
                                xlnx,ipi-buf-index = <0x7>;
                                phandle = <0xe6>;
                        };

                        versal_cips_0_pspmc_0_psv_ipi_pmc_nobuf_6: child@6 {
                                xlnx,ipi-bitmask = <0x200>;
                                xlnx,ipi-id = <0x9>;
                                xlnx,ipi-buf-index = <0xffff>;
                                phandle = <0xe7>;
                        };

                        versal_cips_0_pspmc_0_psv_ipi_pmc_nobuf_7: child@7 {
                                xlnx,ipi-bitmask = <0x2>;
                                xlnx,ipi-id = <0x1>;
                                xlnx,ipi-buf-index = <0x1>;
                                phandle = <0xe8>;
                        };

                        versal_cips_0_pspmc_0_psv_ipi_pmc_nobuf_8: child@8 {
                                xlnx,ipi-bitmask = <0x100>;
                                xlnx,ipi-id = <0x8>;
                                xlnx,ipi-buf-index = <0xffff>;
                                phandle = <0xe9>;
                        };

                        versal_cips_0_pspmc_0_psv_ipi_pmc_nobuf_9: child@9 {
                                xlnx,ipi-bitmask = <0x1>;
                                xlnx,ipi-id = <0x0>;
                                xlnx,ipi-buf-index = <0x0>;
                                phandle = <0xea>;
                        };
                };

                versal_cips_0_pspmc_0_psv_cpm: versal_cips_0_pspmc_0_psv_cpm@0 {
                        compatible = "xlnx,psv-cpm-1.0";
                        status = "okay";
                        xlnx,ip-name = "psv_cpm";
                        reg = <0x0 0xfc000000 0x0 0x1000000>;
                        xlnx,name = "versal_cips_0_pspmc_0_psv_cpm";
                        phandle = <0x45>;
                };

                versal_cips_0_pspmc_0_psv_crf_0: versal_cips_0_pspmc_0_psv_crf_0@fd1a0000 {
                        compatible = "xlnx,psv-crf-1.0";
                        status = "okay";
                        xlnx,ip-name = "psv_crf";
                        reg = <0x0 0xfd1a0000 0x0 0x140000>;
                        xlnx,name = "versal_cips_0_pspmc_0_psv_crf_0";
                        phandle = <0x47>;
                };

                versal_cips_0_pspmc_0_psv_crl_0: versal_cips_0_pspmc_0_psv_crl_0@ff5e0000 {
                        compatible = "xlnx,psv-crl-1.0";
                        status = "okay";
                        xlnx,ip-name = "psv_crl";
                        reg = <0x0 0xff5e0000 0x0 0x300000>;
                        xlnx,name = "versal_cips_0_pspmc_0_psv_crl_0";
                        phandle = <0x62>;
                };

                versal_cips_0_pspmc_0_psv_crp_0: versal_cips_0_pspmc_0_psv_crp_0@f1260000 {
                        compatible = "xlnx,psv-crp-1.0";
                        status = "okay";
                        xlnx,ip-name = "psv_crp";
                        reg = <0x0 0xf1260000 0x0 0x10000>;
                        xlnx,name = "versal_cips_0_pspmc_0_psv_crp_0";
                        phandle = <0x3a>;
                };

                versal_cips_0_pspmc_0_psv_fpd_afi_0: versal_cips_0_pspmc_0_psv_fpd_afi_0@fd360000 {
                        compatible = "xlnx,psv-fpd-afi-1.0";
                        status = "okay";
                        xlnx,ip-name = "psv_fpd_afi";
                        reg = <0x0 0xfd360000 0x0 0x10000>;
                        xlnx,name = "versal_cips_0_pspmc_0_psv_fpd_afi_0";
                        phandle = <0x48>;
                };

                versal_cips_0_pspmc_0_psv_fpd_afi_2: versal_cips_0_pspmc_0_psv_fpd_afi_2@fd380000 {
                        compatible = "xlnx,psv-fpd-afi-1.0";
                        status = "okay";
                        xlnx,ip-name = "psv_fpd_afi";
                        reg = <0x0 0xfd380000 0x0 0x10000>;
                        xlnx,name = "versal_cips_0_pspmc_0_psv_fpd_afi_2";
                        phandle = <0x49>;
                };

                versal_cips_0_pspmc_0_psv_fpd_cci_0: versal_cips_0_pspmc_0_psv_fpd_cci_0@fd5e0000 {
                        compatible = "xlnx,psv-fpd-cci-1.0";
                        status = "okay";
                        xlnx,ip-name = "psv_fpd_cci";
                        reg = <0x0 0xfd5e0000 0x0 0x10000>;
                        xlnx,name = "versal_cips_0_pspmc_0_psv_fpd_cci_0";
                        phandle = <0x4c>;
                };

                versal_cips_0_pspmc_0_psv_fpd_gpv_0: versal_cips_0_pspmc_0_psv_fpd_gpv_0@fd700000 {
                        compatible = "xlnx,psv-fpd-gpv-1.0";
                        status = "okay";
                        xlnx,ip-name = "psv_fpd_gpv";
                        reg = <0x0 0xfd700000 0x0 0x100000>;
                        xlnx,name = "versal_cips_0_pspmc_0_psv_fpd_gpv_0";
                        phandle = <0x50>;
                };

                versal_cips_0_pspmc_0_psv_fpd_slcr_0: versal_cips_0_pspmc_0_psv_fpd_slcr_0@fd610000 {
                        compatible = "xlnx,psv-fpd-slcr-1.0";
                        status = "okay";
                        xlnx,ip-name = "psv_fpd_slcr";
                        reg = <0x0 0xfd610000 0x0 0x10000>;
                        xlnx,name = "versal_cips_0_pspmc_0_psv_fpd_slcr_0";
                        phandle = <0x4e>;
                };

                versal_cips_0_pspmc_0_psv_fpd_slcr_secure_0: versal_cips_0_pspmc_0_psv_fpd_slcr_secure_0@fd690000 {
                        compatible = "xlnx,psv-fpd-slcr-secure-1.0";
                        status = "okay";
                        xlnx,ip-name = "psv_fpd_slcr_secure";
                        reg = <0x0 0xfd690000 0x0 0x10000>;
                        xlnx,name = "versal_cips_0_pspmc_0_psv_fpd_slcr_secure_0";
                        phandle = <0x4f>;
                };

                versal_cips_0_pspmc_0_psv_fpd_smmu_0: versal_cips_0_pspmc_0_psv_fpd_smmu_0@fd5f0000 {
                        compatible = "xlnx,psv-fpd-smmu-1.0";
                        status = "okay";
                        xlnx,ip-name = "psv_fpd_smmu";
                        reg = <0x0 0xfd5f0000 0x0 0x10000>;
                        xlnx,name = "versal_cips_0_pspmc_0_psv_fpd_smmu_0";
                        phandle = <0x4d>;
                };

                versal_cips_0_pspmc_0_psv_lpd_afi_0: versal_cips_0_pspmc_0_psv_lpd_afi_0@ff9b0000 {
                        compatible = "xlnx,psv-lpd-afi-1.0";
                        status = "okay";
                        xlnx,ip-name = "psv_lpd_afi";
                        reg = <0x0 0xff9b0000 0x0 0x10000>;
                        xlnx,name = "versal_cips_0_pspmc_0_psv_lpd_afi_0";
                        phandle = <0x67>;
                };

                versal_cips_0_pspmc_0_psv_lpd_iou_secure_slcr_0: versal_cips_0_pspmc_0_psv_lpd_iou_secure_slcr_0@ff0a0000 {
                        compatible = "xlnx,psv-lpd-iou-secure-slcr-1.0";
                        status = "okay";
                        xlnx,ip-name = "psv_lpd_iou_secure_slcr";
                        reg = <0x0 0xff0a0000 0x0 0x10000>;
                        xlnx,name = "versal_cips_0_pspmc_0_psv_lpd_iou_secure_slcr_0";
                        phandle = <0x58>;
                };

                versal_cips_0_pspmc_0_psv_lpd_iou_slcr_0: versal_cips_0_pspmc_0_psv_lpd_iou_slcr_0@ff080000 {
                        compatible = "xlnx,psv-lpd-iou-slcr-1.0";
                        status = "okay";
                        xlnx,ip-name = "psv_lpd_iou_slcr";
                        reg = <0x0 0xff080000 0x0 0x20000>;
                        xlnx,name = "versal_cips_0_pspmc_0_psv_lpd_iou_slcr_0";
                        phandle = <0x57>;
                };

                versal_cips_0_pspmc_0_psv_lpd_slcr_0: versal_cips_0_pspmc_0_psv_lpd_slcr_0@ff410000 {
                        compatible = "xlnx,psv-lpd-slcr-1.0";
                        status = "okay";
                        xlnx,ip-name = "psv_lpd_slcr";
                        reg = <0x0 0xff410000 0x0 0x100000>;
                        xlnx,name = "versal_cips_0_pspmc_0_psv_lpd_slcr_0";
                        phandle = <0x60>;
                };

                versal_cips_0_pspmc_0_psv_lpd_slcr_secure_0: versal_cips_0_pspmc_0_psv_lpd_slcr_secure_0@ff510000 {
                        compatible = "xlnx,psv-lpd-slcr-secure-1.0";
                        status = "okay";
                        xlnx,ip-name = "psv_lpd_slcr_secure";
                        reg = <0x0 0xff510000 0x0 0x40000>;
                        xlnx,name = "versal_cips_0_pspmc_0_psv_lpd_slcr_secure_0";
                        phandle = <0x61>;
                };

                versal_cips_0_pspmc_0_psv_ocm_ctrl: versal_cips_0_pspmc_0_psv_ocm_ctrl@ff960000 {
                        compatible = "xlnx,psv-ocm-1.0";
                        status = "okay";
                        power-domains = <&versal_firmware 0x18314007>;
                        xlnx,ip-name = "psv_ocm";
                        reg = <0x0 0xff960000 0x0 0x10000>;
                        xlnx,name = "versal_cips_0_pspmc_0_psv_ocm_ctrl";
                        phandle = <0x63>;
                };

                versal_cips_0_pspmc_0_psv_pmc_aes: versal_cips_0_pspmc_0_psv_pmc_aes@f11e0000 {
                        compatible = "xlnx,psv-pmc-aes-1.0";
                        status = "okay";
                        xlnx,ip-name = "psv_pmc_aes";
                        reg = <0x0 0xf11e0000 0x0 0x10000>;
                        xlnx,name = "versal_cips_0_pspmc_0_psv_pmc_aes";
                        phandle = <0x32>;
                };

                versal_cips_0_pspmc_0_psv_pmc_analog_0: versal_cips_0_pspmc_0_psv_pmc_analog_0@f1160000 {
                        compatible = "xlnx,psv-pmc-analog-1.0";
                        status = "okay";
                        xlnx,ip-name = "psv_pmc_analog";
                        reg = <0x0 0xf1160000 0x0 0x30000>;
                        xlnx,npi-scan = <0x0>;
                        xlnx,event-log = <0x0>;
                        xlnx,cram-scan = <0x0>;
                        xlnx,name = "versal_cips_0_pspmc_0_psv_pmc_analog_0";
                        phandle = <0x2e>;
                };

                versal_cips_0_pspmc_0_psv_pmc_bbram_ctrl: versal_cips_0_pspmc_0_psv_pmc_bbram_ctrl@f11f0000 {
                        compatible = "xlnx,psv-pmc-bbram-ctrl-1.0";
                        status = "okay";
                        xlnx,ip-name = "psv_pmc_bbram_ctrl";
                        reg = <0x0 0xf11f0000 0x0 0x10000>;
                        xlnx,name = "versal_cips_0_pspmc_0_psv_pmc_bbram_ctrl";
                        phandle = <0x33>;
                };

                versal_cips_0_pspmc_0_psv_pmc_efuse_cache: versal_cips_0_pspmc_0_psv_pmc_efuse_cache@f1250000 {
                        compatible = "xlnx,psv-pmc-efuse-cache-1.0";
                        status = "okay";
                        xlnx,ip-name = "psv_pmc_efuse_cache";
                        reg = <0x0 0xf1250000 0x0 0x10000>;
                        xlnx,name = "versal_cips_0_pspmc_0_psv_pmc_efuse_cache";
                        phandle = <0x39>;
                };

                versal_cips_0_pspmc_0_psv_pmc_efuse_ctrl: versal_cips_0_pspmc_0_psv_pmc_efuse_ctrl@f1240000 {
                        compatible = "xlnx,psv-pmc-efuse-ctrl-1.0";
                        status = "okay";
                        xlnx,ip-name = "psv_pmc_efuse_ctrl";
                        reg = <0x0 0xf1240000 0x0 0x10000>;
                        xlnx,name = "versal_cips_0_pspmc_0_psv_pmc_efuse_ctrl";
                        phandle = <0x38>;
                };

                versal_cips_0_pspmc_0_psv_pmc_global_0: versal_cips_0_pspmc_0_psv_pmc_global_0@f1110000 {
                        compatible = "xlnx,psv-pmc-global-1.0";
                        status = "okay";
                        xlnx,ip-name = "psv_pmc_global";
                        reg = <0x0 0xf1110000 0x0 0x50000>;
                        xlnx,npi-scan = <0x0>;
                        xlnx,event-log = <0x0>;
                        xlnx,cram-scan = <0x0>;
                        xlnx,name = "versal_cips_0_pspmc_0_psv_pmc_global_0";
                        phandle = <0x2d>;
                };

                versal_cips_0_pspmc_0_psv_pmc_ram_data_cntlr: versal_cips_0_pspmc_0_psv_pmc_ram_data_cntlr@f0240000 {
                        xlnx,edk-special = "BRAM_CTRL";
                        xlnx,write-access = <0x2>;
                        compatible = "xlnx,ram-data-cntlr-1.0";
                        xlnx,ecc-onoff-register = <0x1>;
                        xlnx,ecc-onoff-reset-value = <0x1>;
                        xlnx,s-axi-ctrl-protocol = "AXI4LITE";
                        xlnx,mask = <0xffffffff 0xffffe000>;
                        xlnx,mask1 = <0xffffffff 0xffffe000>;
                        xlnx,s-axi-ctrl-aclk-freq-hz = <0x5f5e100>;
                        xlnx,mask2 = <0x800000>;
                        xlnx,fault-inject = <0x1>;
                        xlnx,mask3 = <0x800000>;
                        xlnx,ip-name = "ram_data_cntlr";
                        xlnx,num-lmb = <0x2>;
                        reg = <0x0 0xf0240000 0x0 0x20000>;
                        xlnx,s-axi-ctrl-addr-width = <0x20>;
                        xlnx,ecc-status-registers = <0x1>;
                        xlnx,ce-counter-width = <0x10>;
                        xlnx,ecc = <0x1>;
                        xlnx,edk-iptype = "PERIPHERAL";
                        xlnx,lmb-dwidth = <0x20>;
                        xlnx,interconnect = <0x2>;
                        xlnx,ce-failing-registers = <0x1>;
                        xlnx,ue-failing-registers = <0x1>;
                        status = "okay";
                        xlnx,s-axi-ctrl-data-width = <0x20>;
                        xlnx,bram-awidth = <0x20>;
                        xlnx,lmb-awidth = <0x20>;
                        xlnx,name = "versal_cips_0_pspmc_0_psv_pmc_ram_data_cntlr";
                        phandle = <0x7c>;
                };

                versal_cips_0_pspmc_0_psv_pmc_ram_instr_cntlr: versal_cips_0_pspmc_0_psv_pmc_ram_instr_cntlr@f0200000 {
                        xlnx,edk-special = "BRAM_CTRL";
                        xlnx,write-access = <0x2>;
                        compatible = "xlnx,ram-instr-cntlr-1.0";
                        xlnx,ecc-onoff-register = <0x1>;
                        xlnx,ecc-onoff-reset-value = <0x1>;
                        xlnx,s-axi-ctrl-protocol = "AXI4LITE";
                        xlnx,mask = <0xfffe0000>;
                        xlnx,mask1 = <0xfffe0000>;
                        xlnx,s-axi-ctrl-aclk-freq-hz = <0x5f5e100>;
                        xlnx,mask2 = <0x800000>;
                        xlnx,fault-inject = <0x1>;
                        xlnx,mask3 = <0x800000>;
                        xlnx,ip-name = "ram_instr_cntlr";
                        xlnx,num-lmb = <0x2>;
                        reg = <0x0 0xf0200000 0x0 0x40000>;
                        xlnx,s-axi-ctrl-addr-width = <0x20>;
                        xlnx,ecc-status-registers = <0x1>;
                        xlnx,ce-counter-width = <0x10>;
                        xlnx,ecc = <0x1>;
                        xlnx,edk-iptype = "PERIPHERAL";
                        xlnx,lmb-dwidth = <0x20>;
                        xlnx,interconnect = <0x2>;
                        xlnx,ce-failing-registers = <0x1>;
                        xlnx,ue-failing-registers = <0x1>;
                        status = "okay";
                        xlnx,s-axi-ctrl-data-width = <0x20>;
                        xlnx,bram-awidth = <0x20>;
                        xlnx,lmb-awidth = <0x20>;
                        xlnx,name = "versal_cips_0_pspmc_0_psv_pmc_ram_instr_cntlr";
                        phandle = <0x7b>;
                };

                versal_cips_0_pspmc_0_psv_pmc_ram_npi: versal_cips_0_pspmc_0_psv_pmc_ram_npi@f6000000 {
                        compatible = "xlnx,psv-pmc-ram-npi-1.0";
                        status = "okay";
                        xlnx,ip-name = "psv_pmc_ram_npi";
                        reg = <0x0 0xf6000000 0x0 0x2000000>;
                        xlnx,name = "versal_cips_0_pspmc_0_psv_pmc_ram_npi";
                        phandle = <0x43>;
                };

                versal_cips_0_pspmc_0_psv_pmc_rsa: versal_cips_0_pspmc_0_psv_pmc_rsa@f1200000 {
                        compatible = "xlnx,psv-pmc-rsa-1.0";
                        status = "okay";
                        xlnx,ip-name = "psv_pmc_rsa";
                        reg = <0x0 0xf1200000 0x0 0x10000>;
                        xlnx,name = "versal_cips_0_pspmc_0_psv_pmc_rsa";
                        phandle = <0x34>;
                };

                versal_cips_0_pspmc_0_psv_pmc_sha: versal_cips_0_pspmc_0_psv_pmc_sha@f1210000 {
                        compatible = "xlnx,psv-pmc-sha-1.0";
                        status = "okay";
                        xlnx,ip-name = "psv_pmc_sha";
                        reg = <0x0 0xf1210000 0x0 0x10000>;
                        xlnx,name = "versal_cips_0_pspmc_0_psv_pmc_sha";
                        phandle = <0x35>;
                };

                versal_cips_0_pspmc_0_psv_pmc_slave_boot: versal_cips_0_pspmc_0_psv_pmc_slave_boot@f1220000 {
                        xlnx,device-id = <0x0>;
                        compatible = "xlnx,psv-pmc-slave-boot-1.0";
                        status = "okay";
                        xlnx,ip-name = "psv_pmc_slave_boot";
                        reg = <0x0 0xf1220000 0x0 0x10000>;
                        xlnx,name = "versal_cips_0_pspmc_0_psv_pmc_slave_boot";
                        phandle = <0x36>;
                };

                versal_cips_0_pspmc_0_psv_pmc_slave_boot_stream: versal_cips_0_pspmc_0_psv_pmc_slave_boot_stream@f2100000 {
                        xlnx,device-id = <0x0>;
                        compatible = "xlnx,psv-pmc-slave-boot-stream-1.0";
                        status = "okay";
                        xlnx,ip-name = "psv_pmc_slave_boot_stream";
                        reg = <0x0 0xf2100000 0x0 0x10000>;
                        xlnx,name = "versal_cips_0_pspmc_0_psv_pmc_slave_boot_stream";
                        phandle = <0x42>;
                };

                versal_cips_0_pspmc_0_psv_pmc_tap: versal_cips_0_pspmc_0_psv_pmc_tap@f11a0000 {
                        compatible = "xlnx,psv-pmc-tap-1.0";
                        status = "okay";
                        xlnx,ip-name = "psv_pmc_tap";
                        reg = <0x0 0xf11a0000 0x0 0x20000>;
                        xlnx,name = "versal_cips_0_pspmc_0_psv_pmc_tap";
                        phandle = <0x2f>;
                };

                versal_cips_0_pspmc_0_psv_pmc_tmr_inject_0: versal_cips_0_pspmc_0_psv_pmc_tmr_inject_0@f0083000 {
                        compatible = "xlnx,tmr-inject-1.0";
                        xlnx,cpu-id = <0x1>;
                        xlnx,edk-special = "tmr_inject";
                        xlnx,mask = <0x84000>;
                        xlnx,ip-name = "tmr_inject";
                        reg = <0x0 0xf0083000 0x0 0x1000>;
                        xlnx,magic = <0x27>;
                        xlnx,lmb-dwidth = <0x20>;
                        xlnx,edk-iptype = "PROCESSOR";
                        status = "okay";
                        xlnx,name = "versal_cips_0_pspmc_0_psv_pmc_tmr_inject_0";
                        xlnx,lmb-awidth = <0x20>;
                        phandle = <0x7a>;
                };

                versal_cips_0_pspmc_0_psv_pmc_tmr_manager_0: versal_cips_0_pspmc_0_psv_pmc_tmr_manager_0@f0283000 {
                        xlnx,edk-special = "BRAM_CTRL";
                        xlnx,use-debug-disable = <0x0>;
                        xlnx,sem-interface-type = <0x1>;
                        compatible = "xlnx,tmr-manager-1.0";
                        xlnx,magic1 = <0x0>;
                        xlnx,tmr = <0x1>;
                        xlnx,magic2 = <0x0>;
                        xlnx,brk-delay-rst-value = <0x0>;
                        xlnx,mask = <0x83000>;
                        xlnx,sem-heartbeat-watchdog-width = <0xa>;
                        xlnx,watchdog-width = <0x1e>;
                        xlnx,use-tmr-disable = <0x0>;
                        xlnx,ue-width = <0x3>;
                        xlnx,ip-name = "tmr_manager";
                        xlnx,async-ff = <0x2>;
                        xlnx,ue-is-fatal = <0x0>;
                        xlnx,sem-heartbeat-watchdog = <0x0>;
                        reg = <0x0 0xf0283000 0x0 0x1000>;
                        xlnx,brk-delay-width = <0x0>;
                        xlnx,watchdog = <0x0>;
                        xlnx,sem-interface = <0x0>;
                        xlnx,edk-iptype = "PERIPHERAL";
                        xlnx,mask-rst-value = <0xffffffff 0xffffffff>;
                        xlnx,comparators-mask = <0x0>;
                        xlnx,lmb-dwidth = <0x20>;
                        xlnx,test-comparator = <0x0>;
                        xlnx,strict-miscompare = <0x0>;
                        status = "okay";
                        xlnx,no-of-comparators = <0x1>;
                        xlnx,sem-async = <0x0>;
                        xlnx,name = "versal_cips_0_pspmc_0_psv_pmc_tmr_manager_0";
                        xlnx,lmb-awidth = <0x20>;
                        phandle = <0x7e>;
                };

                versal_cips_0_pspmc_0_psv_psm_global_reg: versal_cips_0_pspmc_0_psv_psm_global_reg@ffc90000 {
                        compatible = "xlnx,psv-psm-global-reg-1.0";
                        status = "okay";
                        xlnx,ip-name = "psv_psm_global_reg";
                        reg = <0x0 0xffc90000 0x0 0xf000>;
                        xlnx,name = "versal_cips_0_pspmc_0_psv_psm_global_reg";
                        phandle = <0x70>;
                };

                versal_cips_0_pspmc_0_psv_r5_0_atcm: versal_cips_0_pspmc_0_psv_r5_0_atcm@0 {
                        xlnx,power-domain = <0x1831800b>;
                        compatible = "xlnx,psv-r5-tcm-1.0";
                        status = "okay";
                        xlnx,ip-name = "psv_r5_tcm";
                        xlnx,bank-size = <0x10000>;
                        reg = <0x0 0x0 0x0 0x10000>;
                        xlnx,name = "versal_cips_0_pspmc_0_psv_r5_0_atcm";
                        phandle = <0x88>;
                };

                versal_cips_0_pspmc_0_psv_r5_0_atcm_lockstep: versal_cips_0_pspmc_0_psv_r5_0_atcm_lockstep@ffe10000 {
                        compatible = "xlnx,psv-r5-0-atcm-lockstep-1.0", "mmio-sram";
                        status = "okay";
                        power-domains = <&versal_firmware 0x1831800b>;
                        xlnx,ip-name = "psv_r5_0_atcm_lockstep";
                        xlnx,is-hierarchy;
                        reg = <0x0 0xffe10000 0x0 0x10000>;
                        xlnx,name = "versal_cips_0_pspmc_0_psv_r5_0_atcm_lockstep";
                        phandle = <0x140>;
                };

                versal_cips_0_pspmc_0_psv_r5_0_btcm: versal_cips_0_pspmc_0_psv_r5_0_btcm@20000 {
                        xlnx,power-domain = <0x1831800c>;
                        compatible = "xlnx,psv-r5-tcm-1.0";
                        status = "okay";
                        xlnx,ip-name = "psv_r5_tcm";
                        xlnx,bank-size = <0x10000>;
                        reg = <0x0 0x20000 0x0 0x10000>;
                        xlnx,name = "versal_cips_0_pspmc_0_psv_r5_0_btcm";
                        phandle = <0x8a>;
                };

                versal_cips_0_pspmc_0_psv_r5_0_btcm_lockstep: versal_cips_0_pspmc_0_psv_r5_0_btcm_lockstep@ffe30000 {
                        compatible = "xlnx,psv-r5-0-btcm-lockstep-1.0", "mmio-sram";
                        status = "okay";
                        power-domains = <&versal_firmware 0x1831800c>;
                        xlnx,ip-name = "psv_r5_0_btcm_lockstep";
                        xlnx,is-hierarchy;
                        reg = <0x0 0xffe30000 0x0 0x10000>;
                        xlnx,name = "versal_cips_0_pspmc_0_psv_r5_0_btcm_lockstep";
                        phandle = <0x141>;
                };

                versal_cips_0_pspmc_0_psv_r5_1_atcm: versal_cips_0_pspmc_0_psv_r5_1_atcm@0 {
                        xlnx,power-domain = <0x1831800d>;
                        compatible = "xlnx,psv-r5-tcm-1.0";
                        status = "okay";
                        xlnx,ip-name = "psv_r5_tcm";
                        xlnx,bank-size = <0x10000>;
                        reg = <0x0 0x0 0x0 0x10000>;
                        xlnx,name = "versal_cips_0_pspmc_0_psv_r5_1_atcm";
                        phandle = <0x92>;
                };

                versal_cips_0_pspmc_0_psv_r5_1_btcm: versal_cips_0_pspmc_0_psv_r5_1_btcm@20000 {
                        xlnx,power-domain = <0x1831800e>;
                        compatible = "xlnx,psv-r5-tcm-1.0";
                        status = "okay";
                        xlnx,ip-name = "psv_r5_tcm";
                        xlnx,bank-size = <0x10000>;
                        reg = <0x0 0x20000 0x0 0x10000>;
                        xlnx,name = "versal_cips_0_pspmc_0_psv_r5_1_btcm";
                        phandle = <0x93>;
                };

                versal_cips_0_pspmc_0_psv_r5_tcm_ram_0: versal_cips_0_pspmc_0_psv_r5_tcm_ram_0@0 {
                        compatible = "xlnx,psv-r5-tcm-1.0";
                        status = "okay";
                        xlnx,ip-name = "psv_r5_tcm";
                        reg = <0x0 0x0 0x0 0x40000>;
                        xlnx,name = "versal_cips_0_pspmc_0_psv_r5_tcm_ram_0";
                        phandle = <0x89>;
                };

                versal_cips_0_pspmc_0_psv_scntr_0: versal_cips_0_pspmc_0_psv_scntr_0@ff130000 {
                        compatible = "xlnx,psv-scntr-1.0";
                        status = "okay";
                        xlnx,ip-name = "psv_scntr";
                        reg = <0x0 0xff130000 0x0 0x10000>;
                        xlnx,name = "versal_cips_0_pspmc_0_psv_scntr_0";
                        phandle = <0x5e>;
                };

                versal_cips_0_pspmc_0_psv_scntrs_0: versal_cips_0_pspmc_0_psv_scntrs_0@ff140000 {
                        compatible = "xlnx,psv-scntrs-1.0";
                        status = "okay";
                        xlnx,ip-name = "psv_scntrs";
                        reg = <0x0 0xff140000 0x0 0x10000>;
                        xlnx,name = "versal_cips_0_pspmc_0_psv_scntrs_0";
                        phandle = <0x5f>;
                };
        };

        psv_r5_0_atcm_global: psv_r5_0_atcm_global@ffe00000 {
                compatible = "xlnx,psv-tcm-global-1.0", "mmio-sram";
                power-domains = <&versal_firmware 0x1831800b>;
                reg = <0x0 0xffe00000 0x0 0x10000>;
                status = "okay";
                xlnx,ip-name = "psv_tcm_global";
                xlnx,is-hierarchy;
                xlnx,name = "versal_cips_0_pspmc_0_psv_r5_0_atcm_global";
                phandle = <0x71>;
        };

        psv_r5_0_btcm_global: psv_r5_0_btcm_global@ffe20000 {
                compatible = "xlnx,psv-tcm-global-1.0", "mmio-sram";
                power-domains = <&versal_firmware 0x1831800c>;
                reg = <0x0 0xffe20000 0x0 0x10000>;
                status = "okay";
                xlnx,ip-name = "psv_tcm_global";
                xlnx,is-hierarchy;
                xlnx,name = "versal_cips_0_pspmc_0_psv_r5_0_btcm_global";
                phandle = <0x142>;
        };

        psv_r5_1_atcm_global: psv_r5_1_atcm_global@ffe90000 {
                compatible = "xlnx,psv-tcm-global-1.0", "mmio-sram";
                power-domains = <&versal_firmware 0x1831800d>;
                reg = <0x0 0xffe90000 0x0 0x10000>;
                status = "okay";
                xlnx,ip-name = "psv_tcm_global";
                xlnx,name = "versal_cips_0_pspmc_0_psv_r5_1_atcm_global";
                phandle = <0x72>;
        };

        psv_r5_1_btcm_global: psv_r5_1_btcm_global@ffeb0000 {
                compatible = "xlnx,psv-tcm-global-1.0", "mmio-sram";
                power-domains = <&versal_firmware 0x1831800e>;
                reg = <0x0 0xffeb0000 0x0 0x10000>;
                status = "okay";
                xlnx,ip-name = "psv_tcm_global";
                xlnx,name = "versal_cips_0_pspmc_0_psv_r5_1_btcm_global";
                phandle = <0x73>;
        };

        amba_xppu: indirect-bus@1 {
                compatible = "indirect-bus";
                #address-cells = <0x2>;
                #size-cells = <0x2>;
                phandle = <0x143>;

                lpd_xppu: xppu@ff990000 {
                        compatible = "xlnx,xppu";
                        #firewall-cells = <0x0>;
                        reg = <0x0 0xff990000 0x0 0x2000>;
                        status = "okay";
                        xlnx,ip-name = "psv_lpd_xppu";
                        xlnx,name = "versal_cips_0_pspmc_0_psv_lpd_xppu_0";
                        phandle = <0x65>;
                };

                pmc_xppu: xppu@f1310000 {
                        compatible = "xlnx,xppu";
                        #firewall-cells = <0x0>;
                        reg = <0x0 0xf1310000 0x0 0x2000>;
                        status = "okay";
                        xlnx,ip-name = "psv_pmc_xppu";
                        xlnx,name = "versal_cips_0_pspmc_0_psv_pmc_xppu_0";
                        phandle = <0x41>;
                };

                pmc_xppu_npi: xppu@f1300000 {
                        compatible = "xlnx,xppu";
                        #firewall-cells = <0x0>;
                        reg = <0x0 0xf1300000 0x0 0x2000>;
                        status = "okay";
                        xlnx,ip-name = "psv_pmc_xppu_npi";
                        xlnx,name = "versal_cips_0_pspmc_0_psv_pmc_xppu_npi_0";
                        phandle = <0x40>;
                };
        };

        amba_xmpu: indirect-bus@2 {
                compatible = "indirect-bus";
                #address-cells = <0x2>;
                #size-cells = <0x2>;
                phandle = <0x144>;

                fpd_xmpu: xmpu@fd390000 {
                        compatible = "xlnx,xmpu";
                        #firewall-cells = <0x0>;
                        reg = <0x0 0xfd390000 0x0 0x1000>;
                        status = "okay";
                        xlnx,ip-name = "psv_fpd_slave_xmpu";
                        xlnx,name = "versal_cips_0_pspmc_0_psv_fpd_slave_xmpu_0";
                        phandle = <0x4a>;
                };

                pmc_xmpu: xmpu@f12f0000 {
                        compatible = "xlnx,xmpu";
                        #firewall-cells = <0x0>;
                        reg = <0x0 0xf12f0000 0x0 0x1000>;
                        status = "okay";
                        xlnx,ip-name = "psv_pmc_xmpu";
                        xlnx,name = "versal_cips_0_pspmc_0_psv_pmc_xmpu_0";
                        phandle = <0x3f>;
                };

                ocm_xmpu: xmpu@ff980000 {
                        compatible = "xlnx,xmpu";
                        #firewall-cells = <0x0>;
                        reg = <0x0 0xff980000 0x0 0x1000>;
                        status = "okay";
                        xlnx,ip-name = "psv_ocm_xmpu";
                        xlnx,name = "versal_cips_0_pspmc_0_psv_ocm_xmpu_0";
                        phandle = <0x64>;
                };
        };

        pl_alt_ref: pl-alt-ref {
                bootph-all;
                compatible = "fixed-clock";
                #clock-cells = <0x0>;
                clock-frequency = <0x1fca055>;
                clock-output-names = "pl_alt_ref_clk";
                phandle = <0x9f>;
        };

        ref: ref {
                bootph-all;
                compatible = "fixed-clock";
                #clock-cells = <0x0>;
                clock-frequency = <0x1fca034>;
                clock-output-names = "ref_clk";
                phandle = <0x9e>;
        };

        can0_clk: can0-clk {
                #clock-cells = <0x0>;
                compatible = "fixed-factor-clock";
                clocks = <&versal_clk 0x60>;
                clock-div = <0x2>;
                clock-mult = <0x1>;
                clock-output-names = "can0_clk";
                phandle = <0x97>;
        };

        can1_clk: can1-clk {
                #clock-cells = <0x0>;
                compatible = "fixed-factor-clock";
                clocks = <&versal_clk 0x61>;
                clock-div = <0x2>;
                clock-mult = <0x1>;
                clock-output-names = "can1_clk";
                phandle = <0x98>;
        };

        firmware {

                versal_firmware: versal-firmware {
                        compatible = "xlnx,versal-firmware";
                        interrupt-parent = <&imux>;
                        bootph-all;
                        method = "smc";
                        #power-domain-cells = <0x1>;
                        phandle = <0x76>;

                        versal_clk: clock-controller {
                                bootph-all;
                                #clock-cells = <0x1>;
                                compatible = "xlnx,versal-clk";
                                clocks = <&ref>,
                                 <&pl_alt_ref>;
                                clock-names = "ref", "pl_alt_ref";
                                phandle = <0x77>;
                        };

                        zynqmp_power: power-management {
                                compatible = "xlnx,zynqmp-power";
                                phandle = <0x149>;
                        };

                        versal_reset: reset-controller {
                                compatible = "xlnx,versal-reset";
                                #reset-cells = <0x1>;
                                phandle = <0x9b>;
                        };

                        pinctrl0: pinctrl {
                                compatible = "xlnx,versal-pinctrl";
                                phandle = <0x14a>;
                        };

                        versal_sec_cfg: versal-sec-cfg {
                                compatible = "xlnx,versal-sec-cfg";
                                #address-cells = <0x1>;
                                #size-cells = <0x1>;
                                phandle = <0x14b>;

                                nvmem-layout {
                                        compatible = "fixed-layout";
                                        #address-cells = <0x1>;
                                        #size-cells = <0x1>;

                                        bbram_zeroize: bbram-zeroize@4 {
                                                reg = <0x4 0x4>;
                                                phandle = <0x14c>;
                                        };

                                        bbram_key: bbram-key@10 {
                                                reg = <0x10 0x20>;
                                                phandle = <0x14d>;
                                        };

                                        bbram_usr: bbram-usr@30 {
                                                reg = <0x30 0x4>;
                                                phandle = <0x14e>;
                                        };

                                        bbram_lock: bbram-lock@48 {
                                                reg = <0x48 0x4>;
                                                phandle = <0x14f>;
                                        };

                                        user_key0: user-key@110 {
                                                reg = <0x110 0x20>;
                                                phandle = <0x150>;
                                        };

                                        user_key1: user-key@130 {
                                                reg = <0x130 0x20>;
                                                phandle = <0x151>;
                                        };

                                        user_key2: user-key@150 {
                                                reg = <0x150 0x20>;
                                                phandle = <0x152>;
                                        };

                                        user_key3: user-key@170 {
                                                reg = <0x170 0x20>;
                                                phandle = <0x153>;
                                        };

                                        user_key4: user-key@190 {
                                                reg = <0x190 0x20>;
                                                phandle = <0x154>;
                                        };

                                        user_key5: user-key@1b0 {
                                                reg = <0x1b0 0x20>;
                                                phandle = <0x155>;
                                        };

                                        user_key6: user-key@1d0 {
                                                reg = <0x1d0 0x20>;
                                                phandle = <0x156>;
                                        };

                                        user_key7: user-key@1f0 {
                                                reg = <0x1f0 0x20>;
                                                phandle = <0x157>;
                                        };
                                };
                        };
                };
        };

        amba_pl: amba_pl {
                ranges;
                compatible = "simple-bus";
                #address-cells = <0x2>;
                #size-cells = <0x2>;
                firmware-name = "v80_base_pld.pdi";
                phandle = <0x158>;
        };

        axi_noc_0_ddr_memory: memory@00000000 {
                compatible = "xlnx,axi-noc-1.1";
                xlnx,ip-name = "axi_noc";
                device_type = "memory";
                reg = <0x0 0x0 0x0 0x80000000>;
                memory_type = "memory";
                phandle = <0x3>;
        };

        versal_cips_0_pspmc_0_psv_ocm_ram_0_memory: memory@FFFC0000 {
                compatible = "xlnx,psv-ocm-ram-0-1.0", "mmio-sram";
                xlnx,ip-name = "psv_ocm_ram_0";
                device_type = "memory";
                memory_type = "memory";
                reg = <0x0 0xfffc0000 0x0 0x40000>;
                phandle = <0x8>;
        };

        chosen {
                stdout-path = "serial0:115200n8";
        };

        aliases {
                serial0 = "/axi/serial@ff000000";
                serial1 = "/axi/serial@ff010000";
                serial2 = "/axi/coresight@f0800000";
                i2c0 = "/axi/i2c@ff020000";
                i2c1 = "/axi/i2c@ff030000";
                mmc0 = "/axi/mmc@f1040000";
                spi0 = "/axi/spi@f1010000";
                rtc0 = "/axi/rtc@f12a0000";
        };

        __symbols__ {
                cpus_microblaze_0 = "/cpus_microblaze@0";
                psv_pmc_0 = "/cpus_microblaze@0/cpu@0";
                cpu_opp_table = "/opp-table-cpu";
                fpga = "/fpga-region";
                psci = "/psci";
                timer = "/timer";
                versal_fpga = "/versal-fpga";
                sensor0 = "/versal-thermal-sensor";
                versal_thermal = "/thermal-zones/versal-thermal";
                temp_alert = "/thermal-zones/versal-thermal/trips/temp-alert";
                ot_crit = "/thermal-zones/versal-thermal/trips/ot-crit";
                amba_apu = "/apu-bus";
                amba_rpu = "/rpu-bus";
                amba = "/axi";
                imux = "/axi/interrupt-multiplex";
                cci = "/axi/cci@fd000000";
                cci_pmu = "/axi/cci@fd000000/pmu@10000";
                lpd_dma_chan0 = "/axi/dma-controller@ffa80000";
                lpd_dma_chan1 = "/axi/dma-controller@ffa90000";
                lpd_dma_chan2 = "/axi/dma-controller@ffaa0000";
                lpd_dma_chan3 = "/axi/dma-controller@ffab0000";
                lpd_dma_chan4 = "/axi/dma-controller@ffac0000";
                lpd_dma_chan5 = "/axi/dma-controller@ffad0000";
                lpd_dma_chan6 = "/axi/dma-controller@ffae0000";
                lpd_dma_chan7 = "/axi/dma-controller@ffaf0000";
                gpio0 = "/axi/gpio@ff0b0000";
                gpio1 = "/axi/gpio@f1020000";
                i2c0 = "/axi/i2c@ff020000";
                regulator_u50 = "/axi/i2c@ff020000/regulator@60";
                regulator_uXX = "/axi/i2c@ff020000/regulator@61";
                sensor_u30 = "/axi/i2c@ff020000/temp-sensor@1a";
                gpio_u43 = "/axi/i2c@ff020000/gpio@20";
                ina_u48 = "/axi/i2c@ff020000/power-sensor@40";
                ina_u49 = "/axi/i2c@ff020000/power-sensor@41";
                i2c1 = "/axi/i2c@ff030000";
                qsfp_power = "/axi/i2c@ff030000/gpio@21";
                i2c_qsfp1 = "/axi/i2c@ff030000/i2c-mux@70";
                qsfp1 = "/axi/i2c@ff030000/i2c-mux@70/i2c@0/gpio@20";
                qsfp2 = "/axi/i2c@ff030000/i2c-mux@70/i2c@2/gpio@20";
                i2c_qsfp3 = "/axi/i2c@ff030000/i2c-mux@71";
                qsfp3 = "/axi/i2c@ff030000/i2c-mux@71/i2c@0/gpio@20";
                qsfp4 = "/axi/i2c@ff030000/i2c-mux@71/i2c@2/gpio@20";
                pcie = "/axi/i2c@ff030000/i2c-mux@72";
                ocm = "/axi/memory-controller@ff960000";
                rtc = "/axi/rtc@f12a0000";
                sdhci0 = "/axi/mmc@f1040000";
                serial0 = "/axi/serial@ff000000";
                serial1 = "/axi/serial@ff010000";
                smmu = "/axi/iommu@fd800000";
                ospi = "/axi/spi@f1010000";
                ospi_flash = "/axi/spi@f1010000/flash@0";
                spi0 = "/axi/spi@ff040000";
                sysmon0 = "/axi/sysmon@f1270000";
                ttc0 = "/axi/timer@ff0e0000";
                ttc1 = "/axi/timer@ff0f0000";
                ttc2 = "/axi/timer@ff100000";
                ttc3 = "/axi/timer@ff110000";
                dma0 = "/axi/pmcdma@f11c0000";
                dma1 = "/axi/pmcdma@f11d0000";
                pmc_trng = "/axi/pmc_trng@f1230000";
                pmc_cfi_cframe_0 = "/axi/cframe@f12d0000";
                pmc_cfu_apb_0 = "/axi/cfu_apb@f12b0000";
                pmc_ppu1_mdm_0 = "/axi/ppu1_mdm@f0310000";
                iomodule0 = "/axi/iomodule@f0280000";
                ipi_pmc = "/axi/mailbox@ff320000";
                versal_cips_0_pspmc_0_psv_ipi_pmc_0 = "/axi/mailbox@ff320000/child@0";
                versal_cips_0_pspmc_0_psv_ipi_pmc_1 = "/axi/mailbox@ff320000/child@1";
                versal_cips_0_pspmc_0_psv_ipi_pmc_2 = "/axi/mailbox@ff320000/child@2";
                versal_cips_0_pspmc_0_psv_ipi_pmc_3 = "/axi/mailbox@ff320000/child@3";
                versal_cips_0_pspmc_0_psv_ipi_pmc_4 = "/axi/mailbox@ff320000/child@4";
                versal_cips_0_pspmc_0_psv_ipi_pmc_5 = "/axi/mailbox@ff320000/child@5";
                versal_cips_0_pspmc_0_psv_ipi_pmc_6 = "/axi/mailbox@ff320000/child@6";
                versal_cips_0_pspmc_0_psv_ipi_pmc_7 = "/axi/mailbox@ff320000/child@7";
                versal_cips_0_pspmc_0_psv_ipi_pmc_8 = "/axi/mailbox@ff320000/child@8";
                versal_cips_0_pspmc_0_psv_ipi_pmc_9 = "/axi/mailbox@ff320000/child@9";
                ipi_pmc_nobuf = "/axi/mailbox@ff390000";
                versal_cips_0_pspmc_0_psv_ipi_pmc_nobuf_0 = "/axi/mailbox@ff390000/child@0";
                versal_cips_0_pspmc_0_psv_ipi_pmc_nobuf_1 = "/axi/mailbox@ff390000/child@1";
                versal_cips_0_pspmc_0_psv_ipi_pmc_nobuf_2 = "/axi/mailbox@ff390000/child@2";
                versal_cips_0_pspmc_0_psv_ipi_pmc_nobuf_3 = "/axi/mailbox@ff390000/child@3";
                versal_cips_0_pspmc_0_psv_ipi_pmc_nobuf_4 = "/axi/mailbox@ff390000/child@4";
                versal_cips_0_pspmc_0_psv_ipi_pmc_nobuf_5 = "/axi/mailbox@ff390000/child@5";
                versal_cips_0_pspmc_0_psv_ipi_pmc_nobuf_6 = "/axi/mailbox@ff390000/child@6";
                versal_cips_0_pspmc_0_psv_ipi_pmc_nobuf_7 = "/axi/mailbox@ff390000/child@7";
                versal_cips_0_pspmc_0_psv_ipi_pmc_nobuf_8 = "/axi/mailbox@ff390000/child@8";
                versal_cips_0_pspmc_0_psv_ipi_pmc_nobuf_9 = "/axi/mailbox@ff390000/child@9";
                versal_cips_0_pspmc_0_psv_cpm = "/axi/versal_cips_0_pspmc_0_psv_cpm@0";
                versal_cips_0_pspmc_0_psv_crf_0 = "/axi/versal_cips_0_pspmc_0_psv_crf_0@fd1a0000";
                versal_cips_0_pspmc_0_psv_crl_0 = "/axi/versal_cips_0_pspmc_0_psv_crl_0@ff5e0000";
                versal_cips_0_pspmc_0_psv_crp_0 = "/axi/versal_cips_0_pspmc_0_psv_crp_0@f1260000";
                versal_cips_0_pspmc_0_psv_fpd_afi_0 = "/axi/versal_cips_0_pspmc_0_psv_fpd_afi_0@fd360000";
                versal_cips_0_pspmc_0_psv_fpd_afi_2 = "/axi/versal_cips_0_pspmc_0_psv_fpd_afi_2@fd380000";
                versal_cips_0_pspmc_0_psv_fpd_cci_0 = "/axi/versal_cips_0_pspmc_0_psv_fpd_cci_0@fd5e0000";
                versal_cips_0_pspmc_0_psv_fpd_gpv_0 = "/axi/versal_cips_0_pspmc_0_psv_fpd_gpv_0@fd700000";
                versal_cips_0_pspmc_0_psv_fpd_slcr_0 = "/axi/versal_cips_0_pspmc_0_psv_fpd_slcr_0@fd610000";
                versal_cips_0_pspmc_0_psv_fpd_slcr_secure_0 = "/axi/versal_cips_0_pspmc_0_psv_fpd_slcr_secure_0@fd690000";
                versal_cips_0_pspmc_0_psv_fpd_smmu_0 = "/axi/versal_cips_0_pspmc_0_psv_fpd_smmu_0@fd5f0000";
                versal_cips_0_pspmc_0_psv_lpd_afi_0 = "/axi/versal_cips_0_pspmc_0_psv_lpd_afi_0@ff9b0000";
                versal_cips_0_pspmc_0_psv_lpd_iou_secure_slcr_0 = "/axi/versal_cips_0_pspmc_0_psv_lpd_iou_secure_slcr_0@ff0a0000";
                versal_cips_0_pspmc_0_psv_lpd_iou_slcr_0 = "/axi/versal_cips_0_pspmc_0_psv_lpd_iou_slcr_0@ff080000";
                versal_cips_0_pspmc_0_psv_lpd_slcr_0 = "/axi/versal_cips_0_pspmc_0_psv_lpd_slcr_0@ff410000";
                versal_cips_0_pspmc_0_psv_lpd_slcr_secure_0 = "/axi/versal_cips_0_pspmc_0_psv_lpd_slcr_secure_0@ff510000";
                versal_cips_0_pspmc_0_psv_ocm_ctrl = "/axi/versal_cips_0_pspmc_0_psv_ocm_ctrl@ff960000";
                versal_cips_0_pspmc_0_psv_pmc_aes = "/axi/versal_cips_0_pspmc_0_psv_pmc_aes@f11e0000";
                versal_cips_0_pspmc_0_psv_pmc_analog_0 = "/axi/versal_cips_0_pspmc_0_psv_pmc_analog_0@f1160000";
                versal_cips_0_pspmc_0_psv_pmc_bbram_ctrl = "/axi/versal_cips_0_pspmc_0_psv_pmc_bbram_ctrl@f11f0000";
                versal_cips_0_pspmc_0_psv_pmc_efuse_cache = "/axi/versal_cips_0_pspmc_0_psv_pmc_efuse_cache@f1250000";
                versal_cips_0_pspmc_0_psv_pmc_efuse_ctrl = "/axi/versal_cips_0_pspmc_0_psv_pmc_efuse_ctrl@f1240000";
                versal_cips_0_pspmc_0_psv_pmc_global_0 = "/axi/versal_cips_0_pspmc_0_psv_pmc_global_0@f1110000";
                versal_cips_0_pspmc_0_psv_pmc_ram_data_cntlr = "/axi/versal_cips_0_pspmc_0_psv_pmc_ram_data_cntlr@f0240000";
                versal_cips_0_pspmc_0_psv_pmc_ram_instr_cntlr = "/axi/versal_cips_0_pspmc_0_psv_pmc_ram_instr_cntlr@f0200000";
                versal_cips_0_pspmc_0_psv_pmc_ram_npi = "/axi/versal_cips_0_pspmc_0_psv_pmc_ram_npi@f6000000";
                versal_cips_0_pspmc_0_psv_pmc_rsa = "/axi/versal_cips_0_pspmc_0_psv_pmc_rsa@f1200000";
                versal_cips_0_pspmc_0_psv_pmc_sha = "/axi/versal_cips_0_pspmc_0_psv_pmc_sha@f1210000";
                versal_cips_0_pspmc_0_psv_pmc_slave_boot = "/axi/versal_cips_0_pspmc_0_psv_pmc_slave_boot@f1220000";
                versal_cips_0_pspmc_0_psv_pmc_slave_boot_stream = "/axi/versal_cips_0_pspmc_0_psv_pmc_slave_boot_stream@f2100000";
                versal_cips_0_pspmc_0_psv_pmc_tap = "/axi/versal_cips_0_pspmc_0_psv_pmc_tap@f11a0000";
                versal_cips_0_pspmc_0_psv_pmc_tmr_inject_0 = "/axi/versal_cips_0_pspmc_0_psv_pmc_tmr_inject_0@f0083000";
                versal_cips_0_pspmc_0_psv_pmc_tmr_manager_0 = "/axi/versal_cips_0_pspmc_0_psv_pmc_tmr_manager_0@f0283000";
                versal_cips_0_pspmc_0_psv_psm_global_reg = "/axi/versal_cips_0_pspmc_0_psv_psm_global_reg@ffc90000";
                versal_cips_0_pspmc_0_psv_r5_0_atcm = "/axi/versal_cips_0_pspmc_0_psv_r5_0_atcm@0";
                versal_cips_0_pspmc_0_psv_r5_0_atcm_lockstep = "/axi/versal_cips_0_pspmc_0_psv_r5_0_atcm_lockstep@ffe10000";
                versal_cips_0_pspmc_0_psv_r5_0_btcm = "/axi/versal_cips_0_pspmc_0_psv_r5_0_btcm@20000";
                versal_cips_0_pspmc_0_psv_r5_0_btcm_lockstep = "/axi/versal_cips_0_pspmc_0_psv_r5_0_btcm_lockstep@ffe30000";
                versal_cips_0_pspmc_0_psv_r5_1_atcm = "/axi/versal_cips_0_pspmc_0_psv_r5_1_atcm@0";
                versal_cips_0_pspmc_0_psv_r5_1_btcm = "/axi/versal_cips_0_pspmc_0_psv_r5_1_btcm@20000";
                versal_cips_0_pspmc_0_psv_r5_tcm_ram_0 = "/axi/versal_cips_0_pspmc_0_psv_r5_tcm_ram_0@0";
                versal_cips_0_pspmc_0_psv_scntr_0 = "/axi/versal_cips_0_pspmc_0_psv_scntr_0@ff130000";
                versal_cips_0_pspmc_0_psv_scntrs_0 = "/axi/versal_cips_0_pspmc_0_psv_scntrs_0@ff140000";
                psv_r5_0_atcm_global = "/psv_r5_0_atcm_global@ffe00000";
                psv_r5_0_btcm_global = "/psv_r5_0_btcm_global@ffe20000";
                psv_r5_1_atcm_global = "/psv_r5_1_atcm_global@ffe90000";
                psv_r5_1_btcm_global = "/psv_r5_1_btcm_global@ffeb0000";
                amba_xppu = "/indirect-bus@1";
                lpd_xppu = "/indirect-bus@1/xppu@ff990000";
                pmc_xppu = "/indirect-bus@1/xppu@f1310000";
                pmc_xppu_npi = "/indirect-bus@1/xppu@f1300000";
                amba_xmpu = "/indirect-bus@2";
                fpd_xmpu = "/indirect-bus@2/xmpu@fd390000";
                pmc_xmpu = "/indirect-bus@2/xmpu@f12f0000";
                ocm_xmpu = "/indirect-bus@2/xmpu@ff980000";
                pl_alt_ref = "/pl-alt-ref";
                ref = "/ref";
                can0_clk = "/can0-clk";
                can1_clk = "/can1-clk";
                versal_firmware = "/firmware/versal-firmware";
                versal_clk = "/firmware/versal-firmware/clock-controller";
                zynqmp_power = "/firmware/versal-firmware/power-management";
                versal_reset = "/firmware/versal-firmware/reset-controller";
                pinctrl0 = "/firmware/versal-firmware/pinctrl";
                versal_sec_cfg = "/firmware/versal-firmware/versal-sec-cfg";
                bbram_zeroize = "/firmware/versal-firmware/versal-sec-cfg/nvmem-layout/bbram-zeroize@4";
                bbram_key = "/firmware/versal-firmware/versal-sec-cfg/nvmem-layout/bbram-key@10";
                bbram_usr = "/firmware/versal-firmware/versal-sec-cfg/nvmem-layout/bbram-usr@30";
                bbram_lock = "/firmware/versal-firmware/versal-sec-cfg/nvmem-layout/bbram-lock@48";
                user_key0 = "/firmware/versal-firmware/versal-sec-cfg/nvmem-layout/user-key@110";
                user_key1 = "/firmware/versal-firmware/versal-sec-cfg/nvmem-layout/user-key@130";
                user_key2 = "/firmware/versal-firmware/versal-sec-cfg/nvmem-layout/user-key@150";
                user_key3 = "/firmware/versal-firmware/versal-sec-cfg/nvmem-layout/user-key@170";
                user_key4 = "/firmware/versal-firmware/versal-sec-cfg/nvmem-layout/user-key@190";
                user_key5 = "/firmware/versal-firmware/versal-sec-cfg/nvmem-layout/user-key@1b0";
                user_key6 = "/firmware/versal-firmware/versal-sec-cfg/nvmem-layout/user-key@1d0";
                user_key7 = "/firmware/versal-firmware/versal-sec-cfg/nvmem-layout/user-key@1f0";
                amba_pl = "/amba_pl";
                axi_noc_0_ddr_memory = "/memory@00000000";
                versal_cips_0_pspmc_0_psv_ocm_ram_0_memory = "/memory@FFFC0000";
        };
};
